AUTOSAR XML (schema 4-2-1)
standard types defined: boolean, float32, float64, sint16, uint16, uint32, uint8, boolean_CompuMethod, boolean_DataConstr, float32_DataConstr, float64_DataConstr, sint16_DataConstr, uint16_DataConstr, uint32_DataConstr, uint8_DataConstr
package /ComponentTypes
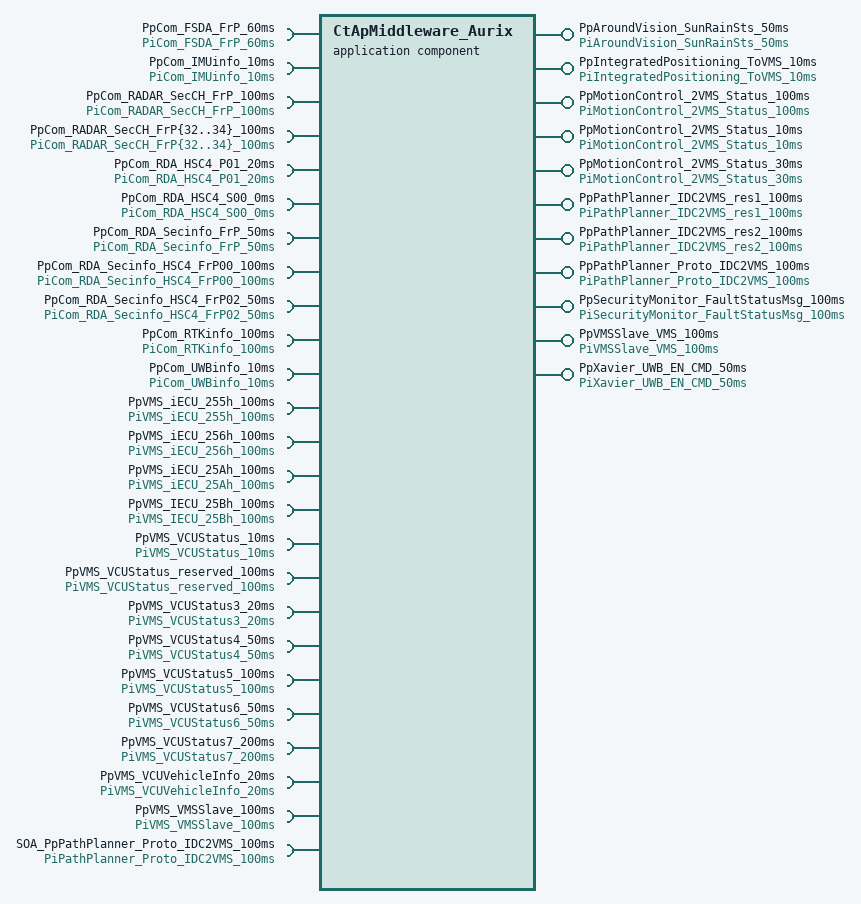
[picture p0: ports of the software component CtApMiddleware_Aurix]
  application sw component type CtApMiddleware_Aurix
    11 x provide port:
      PpAroundVision_SunRainSts_50ms: nonqueued-sender-com-spec{data-element=DeSunRainSts, init-value=constant-reference=C_RECORD_SunRainSts}, provided-interface=PiAroundVision_SunRainSts_50ms
      PpIntegratedPositioning_ToVMS_10ms: nonqueued-sender-com-spec{data-element=DeIntegratedPositioning_ToVMS, init-value=constant-reference=C_RECORD_IntegratedPositioning_ToVMS}, provided-interface=PiIntegratedPositioning_ToVMS_10ms
      PpMotionControl_2VMS_Status_100ms: provided-interface=PiMotionControl_2VMS_Status_100ms
        provided-com-specs:
          data-element=DeCtrl_IDCCAN_IDCStatus{10..19}, init-value=constant-reference=C_RECORD_Ctrl_IDCCAN_IDCStatus{10..19}
          data-element=DeCtrl_IDCCAN_IDCStatus9, init-value=constant-reference=C_RECORD_Ctrl_IDCCAN_IDCStatus9
      PpMotionControl_2VMS_Status_10ms: provided-interface=PiMotionControl_2VMS_Status_10ms
        provided-com-specs:
          data-element=DeCtrl_IDCCAN_IDCStatus{5..7}, init-value=constant-reference=C_RECORD_Ctrl_IDCCAN_IDCStatus{5..7}
      PpMotionControl_2VMS_Status_30ms: provided-interface=PiMotionControl_2VMS_Status_30ms
        provided-com-specs:
          data-element=DeCtrl_IDCCAN_IDCStatus{1..4}, init-value=constant-reference=C_RECORD_Ctrl_IDCCAN_IDCStatus{1..4}
      PpPathPlanner_IDC2VMS_res1_100ms: nonqueued-sender-com-spec{data-element=DeIDC2VMS_res1, init-value=constant-reference=C_RECORD_IDC2VMS_res1}, provided-interface=PiPathPlanner_IDC2VMS_res1_100ms
      PpPathPlanner_IDC2VMS_res2_100ms: nonqueued-sender-com-spec{data-element=DeIDC2VMS_res2, init-value=constant-reference=C_RECORD_IDC2VMS_res2}, provided-interface=PiPathPlanner_IDC2VMS_res2_100ms
      PpPathPlanner_Proto_IDC2VMS_100ms: nonqueued-sender-com-spec{data-element=DeProto_IDC2VMS, init-value=constant-reference=C_RECORD_Proto_IDC2VMS}, provided-interface=PiPathPlanner_Proto_IDC2VMS_100ms
      PpSecurityMonitor_FaultStatusMsg_100ms: nonqueued-sender-com-spec{data-element=DeFaultStatusMsg, init-value=constant-reference=C_RECORD_FaultStatusMsg}, provided-interface=PiSecurityMonitor_FaultStatusMsg_100ms
      PpVMSSlave_VMS_100ms: nonqueued-sender-com-spec{data-element=DeVMSSlave_VMS, init-value=constant-reference=C_RECORD_VMSSlave_VMS_100ms}, provided-interface=PiVMSSlave_VMS_100ms
      PpXavier_UWB_EN_CMD_50ms: nonqueued-sender-com-spec{data-element=DeUWB_EN_CMD, init-value=constant-reference=C_RECORD_UWB_EN_CMD}, provided-interface=PiXavier_UWB_EN_CMD_50ms
    27 x require port:
      PpCom_FSDA_FrP_60ms: nonqueued-receiver-com-spec{data-element=DeFSDA_FrP_f1_s2, filter=data-filter-type=ALWAYS, init-value=constant-reference=C_ARRAY_32_FSDA_FrP}, required-interface=PiCom_FSDA_FrP_60ms
      PpCom_IMUinfo_10ms: nonqueued-receiver-com-spec{data-element=DeIMUinfo, filter=data-filter-type=ALWAYS, init-value=constant-reference=C_RECORD_IMUinfo}, required-interface=PiCom_IMUinfo_10ms
      PpCom_RADAR_SecCH_FrP_100ms: nonqueued-receiver-com-spec{data-element=DeRADAR_SecCH_FrP_f2_s2, filter=data-filter-type=ALWAYS, init-value=constant-reference=C_ARRAY_32_RADAR_SecCH_FrP}, required-interface=PiCom_RADAR_SecCH_FrP_100ms
      PpCom_RADAR_SecCH_FrP{32..34}_100ms: nonqueued-receiver-com-spec{data-element=DeRADAR_SecCH_FrP{32..34}, filter=data-filter-type=ALWAYS, init-value=constant-reference=C_RECORD_RADAR_SecCH_FrP{32..34}}, required-interface=PiCom_RADAR_SecCH_FrP{32..34}_100ms
      PpCom_RDA_HSC4_P01_20ms: nonqueued-receiver-com-spec{data-element=DeRDA_HSC4_P01, filter=data-filter-type=ALWAYS, init-value=constant-reference=C_RECORD_RDA_HSC4_P01}, required-interface=PiCom_RDA_HSC4_P01_20ms
      PpCom_RDA_HSC4_S00_0ms: nonqueued-receiver-com-spec{data-element=DeRDA_HSC4_S00, filter=data-filter-type=ALWAYS, init-value=constant-reference=C_RECORD_RDA_HSC4_S00}, required-interface=PiCom_RDA_HSC4_S00_0ms
      PpCom_RDA_Secinfo_FrP_50ms: nonqueued-receiver-com-spec{data-element=DeRDA_Secinfo_FrP_f2_s9, filter=data-filter-type=ALWAYS, init-value=constant-reference=C_ARRAY_20_RDA_Secinfo_FrP}, required-interface=PiCom_RDA_Secinfo_FrP_50ms
      PpCom_RDA_Secinfo_HSC4_FrP00_100ms: nonqueued-receiver-com-spec{data-element=DeRDA_Secinfo_HSC4_FrP00, filter=data-filter-type=ALWAYS, init-value=constant-reference=C_RECORD_RDA_Secinfo_HSC4_FrP00}, required-interface=PiCom_RDA_Secinfo_HSC4_FrP00_100ms
      PpCom_RDA_Secinfo_HSC4_FrP02_50ms: nonqueued-receiver-com-spec{data-element=DeRDA_Secinfo_HSC4_FrP02, filter=data-filter-type=ALWAYS, init-value=constant-reference=C_RECORD_RDA_Secinfo_HSC4_FrP02}, required-interface=PiCom_RDA_Secinfo_HSC4_FrP02_50ms
      PpCom_RTKinfo_100ms: nonqueued-receiver-com-spec{data-element=DeRTKinfo, filter=data-filter-type=ALWAYS, init-value=constant-reference=C_RECORD_RTKinfo}, required-interface=PiCom_RTKinfo_100ms
      PpCom_UWBinfo_10ms: nonqueued-receiver-com-spec{data-element=DeUWBinfo, filter=data-filter-type=ALWAYS, init-value=constant-reference=C_RECORD_UWBinfo}, required-interface=PiCom_UWBinfo_10ms
      PpVMS_iECU_255h_100ms: nonqueued-receiver-com-spec{data-element=DeiECU_255h, filter=data-filter-type=ALWAYS, init-value=constant-reference=C_RECORD_iECU_255h}, required-interface=PiVMS_iECU_255h_100ms
      PpVMS_iECU_256h_100ms: nonqueued-receiver-com-spec{data-element=DeiECU_256h, filter=data-filter-type=ALWAYS, init-value=constant-reference=C_RECORD_iECU_256h}, required-interface=PiVMS_iECU_256h_100ms
      PpVMS_iECU_25Ah_100ms: nonqueued-receiver-com-spec{data-element=DeiECU_25Ah, filter=data-filter-type=ALWAYS, init-value=constant-reference=C_RECORD_iECU_25Ah}, required-interface=PiVMS_iECU_25Ah_100ms
      PpVMS_IECU_25Bh_100ms: nonqueued-receiver-com-spec{data-element=DeIECU_25Bh, filter=data-filter-type=ALWAYS, init-value=constant-reference=C_RECORD_IECU_25Bh}, required-interface=PiVMS_IECU_25Bh_100ms
      PpVMS_VCUStatus_10ms: nonqueued-receiver-com-spec{data-element=DeVCUStatus, filter=data-filter-type=ALWAYS, init-value=constant-reference=C_RECORD_VCUStatus}, required-interface=PiVMS_VCUStatus_10ms
      PpVMS_VCUStatus_reserved_100ms: nonqueued-receiver-com-spec{data-element=DeVCUStatus_reserved, filter=data-filter-type=ALWAYS, init-value=constant-reference=C_RECORD_VCUStatus_reserved}, required-interface=PiVMS_VCUStatus_reserved_100ms
      PpVMS_VCUStatus3_20ms: nonqueued-receiver-com-spec{data-element=DeVCUStatus3, filter=data-filter-type=ALWAYS, init-value=constant-reference=C_RECORD_VCUStatus3}, required-interface=PiVMS_VCUStatus3_20ms
      PpVMS_VCUStatus4_50ms: nonqueued-receiver-com-spec{data-element=DeVCUStatus4, filter=data-filter-type=ALWAYS, init-value=constant-reference=C_RECORD_VCUStatus4}, required-interface=PiVMS_VCUStatus4_50ms
      PpVMS_VCUStatus5_100ms: nonqueued-receiver-com-spec{data-element=DeVCUStatus5, filter=data-filter-type=ALWAYS, init-value=constant-reference=C_RECORD_VCUStatus5}, required-interface=PiVMS_VCUStatus5_100ms
      PpVMS_VCUStatus6_50ms: nonqueued-receiver-com-spec{data-element=DeVCUStatus6, filter=data-filter-type=ALWAYS, init-value=constant-reference=C_RECORD_VCUStatus6}, required-interface=PiVMS_VCUStatus6_50ms
      PpVMS_VCUStatus7_200ms: nonqueued-receiver-com-spec{data-element=DeVCUStatus7, filter=data-filter-type=ALWAYS, init-value=constant-reference=C_RECORD_VCUStatus7}, required-interface=PiVMS_VCUStatus7_200ms
      PpVMS_VCUVehicleInfo_20ms: nonqueued-receiver-com-spec{data-element=DeVCUVehicleInfo, filter=data-filter-type=ALWAYS, init-value=constant-reference=C_RECORD_VCUVehicleInfo}, required-interface=PiVMS_VCUVehicleInfo_20ms
      PpVMS_VMSSlave_100ms: nonqueued-receiver-com-spec{data-element=DeVMS_VMSSlave, filter=data-filter-type=ALWAYS, init-value=constant-reference=C_RECORD_VMS_VMSSlave}, required-interface=PiVMS_VMSSlave_100ms
      SOA_PpPathPlanner_Proto_IDC2VMS_100ms: nonqueued-receiver-com-spec{data-element=DeProto_IDC2VMS, filter=data-filter-type=ALWAYS, init-value=constant-reference=C_RECORD_Proto_IDC2VMS}, required-interface=PiPathPlanner_Proto_IDC2VMS_100ms
    behavior CtApMiddleware_Aurix_InternalBehavior
  swc implementation CtApMiddleware_Aurix_Implementation: behavior=CtApMiddleware_Aurix_InternalBehavior
    code-descriptors:
      code Default: artifact-descriptors=autosar-engineering-object={short-label=Default, category=SWSRC}
package /Constants
  110 x constant specification:
    C_ARRAY_10_float32: value-spec=10 x 0
    C_ARRAY_20_RDA_Secinfo_FrP: value-spec=20 x C_RECORD_RDA_Secinfo_FrP
    C_ARRAY_32_FSDA_FrP: value-spec=32 x C_RECORD_FSDA_FrP
    C_ARRAY_32_RADAR_SecCH_FrP: value-spec=32 x C_RECORD_RADAR_SecCH_FrP
    C_RECORD_AccBias_Lcc: value-spec=fields=[AxBiassecinfo:0, AyBiassecinfo:0, AzBiassecinfo:0, Lccsecinfo:0]
    C_RECORD_Acce_AngularVel_X: value-spec=fields=[AccelerationXsecinfo:0, AngularRateXsecinfo:0]
    C_RECORD_Acce_AngularVel_Y: value-spec=fields=[AccelerationYsecinfo:0, AngularRateYsecinfo:0]
    C_RECORD_Acce_AngularVel_Z: value-spec=fields=[AccelerationZsecinfo:0, AngularRateZsecinfo:0]
    C_RECORD_AtterrStatus2: value-spec=fields=[PitchStdsecinfo:0, RollStdsecinfo:0, VelDStdsecinfo:0, VelEStdsecinfo:0, VelNStdsecinfo:0, YawStdsecinfo:0]
    C_RECORD_BaseInfoRTK: value-spec=fields=[EastDistancRTK:0, NorthDistancRTK:0]
    C_RECORD_Ctrl_IDCCAN_IDCStatus1: value-spec=fields=[{short-label=stHeader, constant=C_RECORD_HEADER}, fStrgWhlAngReq_degHSC4:0, bEngToqReqVHSC4:0, bStrgWhlAngGrdReqV_degpsHSC4:0, bStrgWhlAngReqV_degHSC4:0, bStrgWhlToqReqV_NmHSC4:0, fEngToqReqHSC4:0, fStrgWhlAngGrdReq_degpsHSC4:0, fStrgWhlToqReq_NmHSC4:0, PaddingGap16_1:0, PaddingGap16_2:0]
    C_RECORD_Ctrl_IDCCAN_IDCStatus10: value-spec=fields=[{short-label=stHeader, constant=C_RECORD_HEADER}, nRCar2AurixReserve100ms_5:0, nRCar2AurixReserve100ms_6:0, nRCar2AurixReserve100ms_7:0, nRCar2AurixReserve100ms_8:0]
    C_RECORD_Ctrl_IDCCAN_IDCStatus11: value-spec=fields=[{short-label=stHeader, constant=C_RECORD_HEADER}, nRCar2AurixReserve100ms_9:0, nRCar2AurixReserve100ms_10:0, nRCar2AurixReserve100ms_11:0, nRCar2AurixReserve100ms_12:0]
    C_RECORD_Ctrl_IDCCAN_IDCStatus12: value-spec=fields=[{short-label=stHeader, constant=C_RECORD_HEADER}, fRCar2AurixReserve100ms_1:0, fRCar2AurixReserve100ms_2:0, fRCar2AurixReserve100ms_3:0, fRCar2AurixReserve100ms_4:0]
    C_RECORD_Ctrl_IDCCAN_IDCStatus13: value-spec=fields=[{short-label=stHeader, constant=C_RECORD_HEADER}, fRCar2AurixReserve100ms_5:0, fRCar2AurixReserve100ms_6:0, fRCar2AurixReserve100ms_7:0, fRCar2AurixReserve100ms_8:0]
    C_RECORD_Ctrl_IDCCAN_IDCStatus14: value-spec=fields=[{short-label=stHeader, constant=C_RECORD_HEADER}, fRCar2AurixReserve100ms_9:0, fRCar2AurixReserve100ms_10:0, fRCar2AurixReserve100ms_11:0, fRCar2AurixReserve100ms_12:0]
    C_RECORD_Ctrl_IDCCAN_IDCStatus15: value-spec=fields=[{short-label=stHeader, constant=C_RECORD_HEADER}, fRCar2AurixReserve100ms_13:0, fRCar2AurixReserve100ms_14:0, fRCar2AurixReserve100ms_15:0, fRCar2AurixReserve100ms_16:0]
    C_RECORD_Ctrl_IDCCAN_IDCStatus16: value-spec=fields=[{short-label=stHeader, constant=C_RECORD_HEADER}, fRCar2AurixReserve100ms_17:0, fRCar2AurixReserve100ms_18:0, fRCar2AurixReserve100ms_19:0, fRCar2AurixReserve100ms_20:0]
    C_RECORD_Ctrl_IDCCAN_IDCStatus17: value-spec=fields=[{short-label=stHeader, constant=C_RECORD_HEADER}, fRCar2AurixReserve100ms_21:0, fRCar2AurixReserve100ms_22:0, fRCar2AurixReserve100ms_23:0, fRCar2AurixReserve100ms_24:0]
    C_RECORD_Ctrl_IDCCAN_IDCStatus18: value-spec=fields=[{short-label=stHeader, constant=C_RECORD_HEADER}, fRCar2AurixReserve100ms_25:0, fRCar2AurixReserve100ms_26:0, fRCar2AurixReserve100ms_27:0, fRCar2AurixReserve100ms_28:0]
    C_RECORD_Ctrl_IDCCAN_IDCStatus19: value-spec=fields=[{short-label=stHeader, constant=C_RECORD_HEADER}, fRCar2AurixReserve100ms_29:0, fRCar2AurixReserve100ms_30:0, fRCar2AurixReserve100ms_31:0, fRCar2AurixReserve100ms_32:0]
    C_RECORD_Ctrl_IDCCAN_IDCStatus2: value-spec=fields=[{short-label=stHeader, constant=C_RECORD_HEADER}, bDecAccReqV_mpssHSC4:0, bDecPressureReqV_barHSC4:0, bShifterPosReqVHSC4:0, PaddingGap8_1:0, fDecAccReq_mpssHSC4:0, fDecPressureReq_barHSC4:0, nEPBReqHSC4:0, nRCarAlv10msRCHSC4:0, nSCSDriverOffReqHSC4:0, nSCSStandStillReqHSC4:0, nShifterPosReqHSC4:0, PaddingGap8_2:0, PaddingGap16_3:0, PaddingGap16_4:0, PaddingGap16_5:0]
    C_RECORD_Ctrl_IDCCAN_IDCStatus3: value-spec=fields=[{short-label=stHeader, constant=C_RECORD_HEADER}, fRCar2AurixReserve30ms_1:0, fRCar2AurixReserve30ms_2:0, fRCar2AurixReserve30ms_3:0, fRCar2AurixReserve30ms_4:0]
    C_RECORD_Ctrl_IDCCAN_IDCStatus4: value-spec=fields=[{short-label=stHeader, constant=C_RECORD_HEADER}, nRCar2AurixReserve30ms_1:0, nRCar2AurixReserve30ms_2:0, nRCar2AurixReserve30ms_3:0, nRCar2AurixReserve30ms_4:0]
    C_RECORD_Ctrl_IDCCAN_IDCStatus5: value-spec=fields=[{short-label=stHeader, constant=C_RECORD_HEADER}, fRCar2AurixReserve10ms_1:0, fRCar2AurixReserve10ms_2:0, fRCar2AurixReserve10ms_3:0, fRCar2AurixReserve10ms_4:0]
    C_RECORD_Ctrl_IDCCAN_IDCStatus6: value-spec=fields=[{short-label=stHeader, constant=C_RECORD_HEADER}, fRCar2AurixReserve10ms_5:0, fRCar2AurixReserve10ms_6:0, fRCar2AurixReserve10ms_7:0, fRCar2AurixReserve10ms_8:0]
    C_RECORD_Ctrl_IDCCAN_IDCStatus7: value-spec=fields=[{short-label=stHeader, constant=C_RECORD_HEADER}, nRCar2AurixReserve10ms_1:0, nRCar2AurixReserve10ms_2:0, nRCar2AurixReserve10ms_3:0, nRCar2AurixReserve10ms_4:0]
    C_RECORD_Ctrl_IDCCAN_IDCStatus9: value-spec=fields=[{short-label=stHeader, constant=C_RECORD_HEADER}, nRCar2AurixReserve100ms_1:0, nRCar2AurixReserve100ms_2:0, nRCar2AurixReserve100ms_3:0, nRCar2AurixReserve100ms_4:0]
    C_RECORD_Diagnosticmessage: value-spec=fields=[Rightsidequalityofantennasignal:0, Leftsidequalityofantennasignal:0, CANprotocolinternalversion:0, GNSSReceiverstartupstatus:0, AGNSSephemerisreceivedstatus:0, CANdatasendstatus:0, Mobilenetwork:0, RightsideGNSSAntennastatus:0, LeftsideGNSSAntennastatus:0, PaddingGap8_1:0, PaddingGap16_2:0]
    C_RECORD_Diagnosticmessage_IMU: value-spec=fields=[DiffDataLinkBrokensecinfo:0, GNSSAntenasBrokensecinfo:0, GPSMsgErrInIMUsecinfo:0, IECUMsgErrInIMUsecinfo:0]
    C_RECORD_ETC1: value-spec=fields=[TransDrivelineEngaged:0, TransTorqueConverterLockupEngag:0, TransShiftlnProcess:0, PaddingGap8_1:0, TransOutputShaftSpeed:0, PercentClutchSlip:0, EngineMomentaryOverspeedEnable:0, ProgressiveShiftDisable:0, PaddingGap16_2:0, TransInputShaftSpeed:0, SrcAddressCtrlDeviceForTransCtrl:0, PaddingGap8_3:0, PaddingGap16_4:0]
    C_RECORD_FaultStatusMsg: value-spec=fields=[{short-label=stHeader, constant=C_RECORD_HEADER}, FailureBitChassis:0, FailureBitEyeQ4:0, FailureBitIECU:0, FailureBitLidar:0, FailureBitAV:0, FailureBitSV:0, FailureBitCAN:0, FailureBitLoc:0, FailureBitIBOX:0, FailureBitReserved_1:0, {short-label=FailureBitReserved, constant=C_ARRAY_10_float32}, Action:0, FailureBitReserved_2:0, Level:0, PaddingGap16_1:0, PaddingGap16_2:0]
    C_RECORD_FSDA_FrP: value-spec=fields=[FSDA_FrP_yspeed:0, FSDA_FrP_ypoint:0, FSDA_FrP_xspeed:0, FSDA_FrP_xpoint:0, FSDA_FrP_V:0, FSDA_FrP_rollingcn:0, FSDA_FrP_id:0, PaddingGap8_1:0]
    C_RECORD_GPS_ECUStatus: value-spec=fields=[ECUWarningsecinfo:0, GPSHeadingStatussecinfo:0, GPSPosStatussecinfo:0, PaddingGap8_1:0, GPSStatussecinfo:0, GPSVelStatussecinfo:0, GPSWarningsecinfo:0, RTKDelaysecinfo:0, VehiclesStatussecinfo:0, PaddingGap16_2:0]
    C_RECORD_GPSPos_HeadingPrecison: value-spec=fields=[AltSigmaGPSsecinfo:0, HeadingSigmaGPSsecinfo:0, LatSigmaGPSsecinfo:0, LonSigmaGPSsecinfo:0]
    C_RECORD_GPSVel_PitchPrecison: value-spec=fields=[PitchSigmaGPSsecinfo:0, VeldownsigmaGPSsecinfo:0, VeleastsigmaGPSsecinfo:0, VelnorthsigmaGPSsecinfo:0]
    C_RECORD_GyroBias_Kws: value-spec=fields=[GxBiassecinfo:0, GyBiassecinfo:0, GzBiassecinfo:0, Kwssecinfo:0]
    C_RECORD_HEADER: value-spec=fields=[TimeStamp:0, FrameID:0, status:0, Counter:0, PaddingGap16_1:0, PaddingGap16_2:0]
    C_RECORD_HeadingPitchInfoRTK: value-spec=fields=[PitchSigma:0, HeadingSigma:0, PitchRTK:0, HeadingRTK:0]
    C_RECORD_IDC2VMS_res1: value-spec=fields=[{short-label=stHeader, fields=[TimeStamp:0, FrameID:0, PaddingGap8_1:0, Counter:0, PaddingGap16_1:0, PaddingGap16_2:0]}, reseverd_float64:100 x 0]
    C_RECORD_IDC2VMS_res2: value-spec=fields=[{short-label=stHeader, fields=[TimeStamp:0, FrameID:0, PaddingGap8_1:0, Counter:0, PaddingGap16_1:0, PaddingGap16_2:0]}, reserved_float64:100 x 0]
    C_RECORD_iECU_250h: value-spec=fields=SA_AngleValue:0
    C_RECORD_iECU_255h: value-spec=fields=[iECU_PEGSUS_pilotWarning:0, iECU_PEGSUS_pilotStatus:0, PaddingGap16_1:0, iECU_pilotDisableInfo:0, iECU_pilot_OverrideIndicator:0, PaddingGap8_2:0, PaddingGap16_3:0]
    C_RECORD_iECU_256h: value-spec=fields=[iECU_pilot_Steer_Override:0, PaddingGap8_1:0, PaddingGap16_2:0]
    C_RECORD_iECU_25Ah: value-spec=fields=[iECU_PEGSUS_AEBState:0, PaddingGap8_1:0, PaddingGap16_2:0]
    C_RECORD_IECU_25Bh: value-spec=fields=[LockandTwistSwitch:0, PaddingGap8_1:0, PaddingGap16_2:0]
    C_RECORD_IECU_FMS1: value-spec=fields=[HighResolutionTripDistance_FMS:0, HghRsolTotalVehDistance_FMS:0]
    C_RECORD_IECU_FMS2: value-spec=fields=[Byte7:0, ResidualLiquidLevel_FMS:0, PaddingGap16_1:0]
    C_RECORD_IECU1toPegasus: value-spec=fields=[FailureBitODFSIECU1:0, FailureBitActor01:0]
    C_RECORD_IECUInternal: value-spec=fields=[Byte3:0, FailureBitIECU1Internal:0]
    C_RECORD_IMUinfo: value-spec=fields=[{short-label=Acce_AngularVel_X, constant=C_RECORD_Acce_AngularVel_X}, {short-label=Acce_AngularVel_Y, constant=C_RECORD_Acce_AngularVel_Y}, {short-label=Acce_AngularVel_Z, constant=C_RECORD_Acce_AngularVel_Z}, {short-label=AtterrStatus2, constant=C_RECORD_AtterrStatus2}, {short-label=INSAltitude_VelDown, constant=C_RECORD_INSAltitude_VelDown}, {short-label=INSLatitudeInfo, constant=C_RECORD_INSLatitudeInfo}, {short-label=INSLongitudeInfo, constant=C_RECORD_INSLongitudeInfo}, {short-label=NavStatus_Heading, constant=C_RECORD_NavStatus_Heading}, {short-label=Pitch_Roll, constant=C_RECORD_Pitch_Roll}, {short-label=PoserrStatus1, constant=C_RECORD_PoserrStatus1}, {short-label=StatusInfo, constant=C_RECORD_StatusInfo}, {short-label=VelNorthEast, constant=C_RECORD_VelNorthEast}, {short-label=AccBias_Lcc, constant=C_RECORD_AccBias_Lcc}, {short-label=GPS_ECUStatus, constant=C_RECORD_GPS_ECUStatus}, {short-label=GPSPos_HeadingPrecison, constant=C_RECORD_GPSPos_HeadingPrecison}, {short-label=GPSVel_PitchPrecison, constant=C_RECORD_GPSVel_PitchPrecison}, {short-label=GyroBias_Kws, constant=C_RECORD_GyroBias_Kws}, {short-label=INSATB, constant=C_RECORD_INSATB}, {short-label=INSATG, constant=C_RECORD_INSATG}, {short-label=INSLTC_LTG, constant=C_RECORD_INSLTC_LTG}, {short-label=VersionNumber, constant=C_RECORD_VersionNumber}, {short-label=Diagnosticmessage_IMU, constant=C_RECORD_Diagnosticmessage_IMU}, {short-label=INSTIme, constant=C_RECORD_INSTIme}, {short-label=ReservedMsg, constant=C_RECORD_ReservedMsg}]
    C_RECORD_INSAltitude_VelDown: value-spec=fields=[AltitudeINSsecinfo:0, DownVelocitysecinfo:0]
    C_RECORD_INSATB: value-spec=fields=[ATB_pitchsecinfo:0, ATB_rollsecinfo:0, ATB_yawsecinfo:0]
    C_RECORD_INSATG: value-spec=fields=[ATG_pitchsecinfo:0, ATG_rollsecinfo:0, ATG_yawsecinfo:0]
    C_RECORD_INSLatitudeInfo: value-spec=fields=LatitudeINSsecinfo:0
    C_RECORD_INSLongitudeInfo: value-spec=fields=LongitudeINSsecinfo:0
    C_RECORD_INSLTC_LTG: value-spec=fields=[LTC_xsecinfo:0, LTC_ysecinfo:0, LTC_zsecinfo:0, LTG_xsecinfo:0, LTG_ysecinfo:0, LTG_zsecinfo:0]
    C_RECORD_INSTIme: value-spec=fields=[UTCTime_YDM:0, UTCTime_HMSssss_IMU:0]
    C_RECORD_IntegratedPositioning_ToVMS: value-spec=fields=[{short-label=stHeader, fields=[TimeStamp:0, FrameID:0, PaddingGap8_1:0, Counter:0, PaddingGap16_1:0, PaddingGap16_2:0]}, time_sec:0, data_name:0, valid:0, PaddingGap16_1:0, weight:0, {short-label=pos_real, fields=[longitude:0, latitude:0, height:0]}, {short-label=pos_utm_real, fields=[X:0, Y:0, Z:0]}, {short-label=pos_Encryption, fields=[longitude:0, latitude:0, height:0]}, {short-label=pos_utm_Encryption, fields=[X:0, Y:0, Z:0]}, {short-label=vel, fields=[north:0, east:0, down:0]}, {short-label=att, fields=[roll:0, pitch:0, heading:0]}, heading_reverse:0, heading_reverse_flag:0, PaddingGap8_2:0, PaddingGap16_3:0, {short-label=cal_line_acc, fields=[X:0, Y:0, Z:0]}, {short-label=cal_line_anglerate, fields=[X:0, Y:0, Z:0]}, PaddingGap16_4:0, PaddingGap16_5:0, lasttime_sec:0, deltaime:0, PaddingGap16_6:0, PaddingGap16_7:0, {short-label=delta_pos_deg, fields=[longitude:0, latitude:0, height:0]}, {short-label=delta_pos_XYZ, fields=[X:0, Y:0, Z:0]}, {short-label=delta_vel_m_s, fields=[north:0, east:0, down:0]}, {short-label=delta_att_rad, fields=[roll:0, pitch:0, heading:0]}, PaddingGap16_8:0, PaddingGap16_9:0, tag_reserve_double:9 x 9 x 0, tag_reserve_int:9 x 9 x 0, sensor_qosstate:0, couple_flag:0, reset_flag:0, sensor_originaldata_qosstate:0, sensor_dataflowstate:0, crd_def:0, hasbeenusedinkf_flag:0, iIntegratedPositionMode:0, iIntegratedVelMode:0, iIntegratedOrientationMode:0, 0, 0, 0, 0, pos_valid:0, vel_valid:0, att_valid:0, PaddingGap16_10:0, PaddingGap16_11:0, PaddingGap16_12:0, gpstime_sec:0]
    C_RECORD_LatitudeInfoRTK: value-spec=fields=[UTCTime_YMD:0, PaddingGap16_1:0, PaddingGap16_2:0, LatitudeRTK:0]
    C_RECORD_LongitudeInfoRTK: value-spec=fields=[AltitudeRTK:0, PaddingGap16_1:0, PaddingGap16_2:0, LongitudeRTK:0]
    C_RECORD_MasterSlaveRTK: value-spec=fields=[PositionAttitudeStatus:0, DiffAgeInfo:0, DiffBaseIDInfo:0, Baselinelength:0, SatNoInAttitudeRTK:0, SatNoInPositionRTK:0, PaddingGap16_1:0]
    C_RECORD_NavStatus_Heading: value-spec=fields=[ChannelInfosecinfo:0, PaddingGap8_1:0, CurrentGPSTimesecinfo:0, Headingsecinfo:0, NavStatussecinfo:0, PaddingGap8_2:0, PaddingGap16_3:0]
    C_RECORD_Pitch_Roll: value-spec=fields=[Pitchsecinfo:0, Rollsecinfo:0]
    C_RECORD_PoserrStatus1: value-spec=fields=[AltStdsecinfo:0, LatStdsecinfo:0, LonStdsecinfo:0]
    C_RECORD_PositionInfoRTK: value-spec=fields=[UTCTime_HMSssss_RTK:0, SerialNumberRTK:0]
    C_RECORD_PositionSigma: value-spec=fields=[AltSigma:0, LonSigma:0, LatSigma:0]
    C_RECORD_Proto_IDC2VMS: value-spec=fields=[TimeStamp:0, Counter:0, IDCReady:0, PaddingGap8_1:0, IDCDTC:0, IDC2VMSPV:0, NoTechniqueTakeOverValid:0, TaskStage:0, PaddingGap16_2:0, PaddingGap16_3:0, PaddingGap16_4:0, IDCBehavior:0, AdpStatus:0, PaddingGap8_5:0, PaddingGap16_6:0, TrackCoefficiantX1:0, TrackCoefficiantX1V:0, PaddingGap8_7:0, PaddingGap16_8:0, TrackCoefficiantX2:0, TrackCoefficiantX2V:0, PaddingGap8_9:0, PaddingGap16_10:0, TrackCoefficiantX3:0, TrackCoefficiantX3V:0, PaddingGap8_11:0, PaddingGap16_12:0, TrackCoefficiantX4:0, TrackCoefficiantX4V:0, PaddingGap8_13:0, PaddingGap16_14:0, TrackCoefficiantX5:0, TrackCoefficiantX5V:0, PaddingGap8_15:0, PaddingGap16_16:0, TrackCoefficiantY1:0, TrackCoefficiantY1V:0, PaddingGap8_17:0, PaddingGap16_18:0, TrackCoefficiantY2:0, TrackCoefficiantY2V:0, PaddingGap8_19:0, PaddingGap16_20:0, TrackCoefficiantY3:0, TrackCoefficiantY3V:0, PaddingGap8_21:0, PaddingGap16_22:0, TrackCoefficiantY4:0, TrackCoefficiantY4V:0, PaddingGap8_23:0, PaddingGap16_24:0, TrackCoefficiantY5:0, TrackCoefficiantY5V:0, PaddingGap8_25:0, PaddingGap16_26:0, PathLength:0, TrackCoefficiantX1_Global:0, TrackCoefficiantX1V_Global:0, PaddingGap8_27:0, PaddingGap16_28:0, TrackCoefficiantX2_Global:0, TrackCoefficiantX2V_Global:0, PaddingGap8_29:0, PaddingGap16_30:0, TrackCoefficiantX3_Global:0, TrackCoefficiantX3V_Global:0, PaddingGap8_31:0, PaddingGap16_32:0, TrackCoefficiantX4_Global:0, TrackCoefficiantX4V_Global:0, PaddingGap8_33:0, PaddingGap16_34:0, TrackCoefficiantX5_Global:0, TrackCoefficiantX5V_Global:0, PaddingGap8_35:0, PaddingGap16_36:0, TrackCoefficiantY1_Global:0, TrackCoefficiantY1V_Global:0, PaddingGap8_37:0, PaddingGap16_38:0, TrackCoefficiantY2_Global:0, TrackCoefficiantY2V_Global:0, PaddingGap8_39:0, PaddingGap16_40:0, TrackCoefficiantY3_Global:0, TrackCoefficiantY3V_Global:0, PaddingGap8_41:0, PaddingGap16_42:0, TrackCoefficiantY4_Global:0, TrackCoefficiantY4V_Global:0, PaddingGap8_43:0, PaddingGap16_44:0, TrackCoefficiantY5_Global:0, TrackCoefficiantY5V_Global:0, PaddingGap8_45:0, PaddingGap16_46:0, PathLength_Global:0, RoadFollowError:0, FrontRoadFollowError:0, HeadingFollowError:0, PathRadiumMin:0, PathRadiumAvg:0, RounterChange:0, SteeringWheelAngleCmdValid:0, PaddingGap16_47:0, SteeringWheelAngleCmd:0, SteeringWheelAngleGrdCmd:0, IsParkInTaskStage:0, PaddingGap8_48:0, PaddingGap16_49:0, ParkLotTopPointY:0, ParkLotTopPointX:0, ParkLotAngleError:0, TrailerAngle:0, TrailerRoadFollowError:0, IsStraightLineControlMode:0, ChangeLaneMode:0, ReverseMode:0, PaddingGap8_50:0, LaneWidth:0, VehicleSpeedMaxLimit:0, LongitudinalAccRequest:0, VehicleSpeedRequest:0, ShiferPoseRequest:0, PaddingGap8_51:0, PaddingGap16_52:0, DistanceToStop:0, IDCDriveEnvironment:0, BrakeMode:0, DippedBeamLampCmd:0, MainBeamLampCmd:0, LeftDirectionLampCmd:0, RightDirectionLampCmd:0, HornCmd:0, WiperCmd:0, PaddingGap16_53:0, PaddingGap16_54:0, Longitude:0, Latitude:0, Altitude:0, Heading:0, Pitch:0, Roll:0, LongitudinalAcc:0, LateralAcc:0, YawRate:0, Reserved_uint8:10 x 0, Reserved_sint16:10 x 0, PaddingGap16_55:0, Reserved_float32:200 x 0, PaddingGap16_56:0, PaddingGap16_57:0]
    C_RECORD_RADAR_SecCH_FrP: value-spec=fields=[RADAR_SecCH_FrP_ID:0, PaddingGap8_1:0, PaddingGap16_2:0, RADAR_SecCH_FrP_dy:0, RADAR_SecCH_FrP_Vy:0, RADAR_SecCH_FrP_dx:0, RADAR_SecCH_FrP_Vx:0, RADAR_SecCH_FrP_SyncCtr:0, PaddingGap8_3:0, PaddingGap16_4:0, RADAR_SecCH_FrP_wExist:0, RADAR_SecCH_FrP_wObstacle:0]
    C_RECORD_RADAR_SecCH_FrP32: value-spec=fields=[AlignmentFail_SGUSecHS2:0, HWFail_SGUSecHS2:0, OtherFail_SGUSecHS2:0, Sensor_Dirty_SGUSecHS2:0, SGUFailSecHS2:0, SGUObsDataSyncCtrSecHS2:0, PaddingGap16_1:0, SGUObsDataTmspSecHS2:0]
    C_RECORD_RADAR_SecCH_FrP33: value-spec=fields=[AlignmentFail_TGUSecHS2:0, FCWASecHS2:0, PaddingGap16_1:0, FCWTimeToColSecHS2:0, HWFail_TGUSecHS2:0, ObsDataSyncCtrSecHS2:0, PaddingGap16_2:0, ObsDataTmspSecHS2:0, OtherFail_TGUSecHS2:0, PedtrnColWrnngASecHS2:0, Sensor_Dirty_TGUSecHS2:0, TGUFailSecHS2:0]
    C_RECORD_RADAR_SecCH_FrP34: value-spec=fields=[DngrsObjExistSecHS2:0, DngrsObjId_PSecHS2:0, PaddingGap8_1:0, PaddingGap16_2:0, DngrsObjObstacleSecHS2:0, DngrsObjSyncCtr_PSecHS2:0, PaddingGap8_3:0, PaddingGap16_4:0, DngrsPedExistSecHS2:0, DngrsPedObstacleSecHS2:0, DngrsPedtrnId_PSecHS2:0, DngrsPedtrnSyncCtr_PSecHS2:0, PaddingGap16_5:0]
    C_RECORD_RDA_HSC4_P01: value-spec=fields=[BSDSelStssecinfo:0, LCASelStssecinfo:0, RDASwStssecinfo:0, PaddingGap8_1:0]
    C_RECORD_RDA_HSC4_S00: value-spec=fields=[wake_network_RDAsecinfo:0, PaddingGap8_1:0, PaddingGap16_2:0]
    C_RECORD_RDA_Secinfo_FrP: value-spec=fields=[RDA_ttgt1V_secinfo:0, RDA_ttgt1_id_secinfo:0, PaddingGap16_1:0, RDA_ttgt1_xpoint_secinfo:0, RDA_ttgt1_xspeed_secinfo:0, RDA_ttgt1_ypoint_secinfo:0, RDA_ttgt1_yspeed_secinfo:0]
    C_RECORD_RDA_Secinfo_HSC4_FrP00: value-spec=fields=[keep_network_RDAsecinfo:0, PaddingGap8_1:0, PaddingGap16_2:0]
    C_RECORD_RDA_Secinfo_HSC4_FrP02: value-spec=fields=[DOWSelStssecinfo:0, LBSDAndLCAWrnngsecinfo:0, LDOWWrnngsecinfo:0, LRCTAWrnngsecinfo:0, RBSDAndLCAWrnngsecinfo:0, RCTASelStssecinfo:0, RDASysStasecinfo:0, RDOWWrnngsecinfo:0, RRCTAWrnngsecinfo:0, PaddingGap8_1:0, PaddingGap16_2:0]
    C_RECORD_ReservedMsg: value-spec=fields=[arrayuint32:[0, 0, 0, 0], arrayfloat64:[0, 0, 0, 0]]
    C_RECORD_RTKinfo: value-spec=fields=[{short-label=BaseInfoRTK, constant=C_RECORD_BaseInfoRTK}, {short-label=Diagnosticmessage, constant=C_RECORD_Diagnosticmessage}, {short-label=HeadingPitchInfoRTK, constant=C_RECORD_HeadingPitchInfoRTK}, PaddingGap16_1:0, PaddingGap16_2:0, {short-label=LatitudeInfoRTK, constant=C_RECORD_LatitudeInfoRTK}, {short-label=LongitudeInfoRTK, constant=C_RECORD_LongitudeInfoRTK}, {short-label=MasterSlaveRTK, constant=C_RECORD_MasterSlaveRTK}, {short-label=PositionInfoRTK, constant=C_RECORD_PositionInfoRTK}, {short-label=PositionSigma, constant=C_RECORD_PositionSigma}, {short-label=VelocityInfoRTK, constant=C_RECORD_VelocityInfoRTK}, {short-label=VelocitySigma, constant=C_RECORD_VelocitySigma}, {short-label=ReservedMsg, constant=C_RECORD_ReservedMsg}]
    C_RECORD_StatusInfo: value-spec=fields=[ECUDelaysecinfo:0, ECUFreqsecinfo:0, GPSDelaysecinfo:0, GPSFreqsecinfo:0, INSDelaysecinfo:0, INSStatussecinfo:0, INSWarningsecinfo:0]
    C_RECORD_SunRainSts: value-spec=fields=[SunSts:0, RainSts:0, res_uint16:0, res_uint32:0]
    C_RECORD_UWB_EN_CMD: value-spec=fields=[UWBLocEnCmdFlag:0, PaddingGap8_1:0, UWBLocEnAreaNo:0, UWBLocEnAreaAttr:0, UWBLocEn:0, PaddingGap16_2:0]
    C_RECORD_UWB_LOC: value-spec=fields=[UWBLocAreaNo:0, UWBLocAreaAttr:0, PaddingGap8_1:0, UWBLocY:0, UWBLocX:0, UWBLocCredit:0, UWBLocXUnit:0, UWBLocYUnit:0, UWBLocType:0, UWBLocRollingCounter:0, PaddingGap8_2:0, PaddingGap16_3:0]
    C_RECORD_UWB_STATUS: value-spec=fields=[UWBLocExptTimes:0, UWBLocFailTimes:0, UWBAchRxTimes:0, UWBAchTxTimes:0, UWBUwbRxTimes:0, UWBUwbTxTimes:0, UWBHwStatas6vTemp:0, UWBHwStatas5v2v5:0, UWBHwStatas3v3:0, UWBHwStatas1v2:0, UWBRfStatus:0, UWBDsaStatus:0, UWBLogicStatus:0, UWBAchStatus:0, UWBHwStatusType:0, UWBLocEnErrFlg:0, UWBLocEnStep:0, UWBLocEnStatus:0, UWBStatusHeader:0, UWBTagType:0]
    C_RECORD_UWBinfo: value-spec=fields=[{short-label=UWB_LOC, constant=C_RECORD_UWB_LOC}, {short-label=UWB_STATUS, constant=C_RECORD_UWB_STATUS}]
    C_RECORD_VCUStatus: value-spec=fields=[{short-label=stHeader, constant=C_RECORD_HEADER}, {short-label=ETC1, constant=C_RECORD_ETC1}, {short-label=VCUStatus1, constant=C_RECORD_VCUStatus1}, {short-label=VCUStatus2, constant=C_RECORD_VCUStatus2}, {short-label=VCUStatus8, constant=C_RECORD_VCUStatus8}, {short-label=VCUStatus10, constant=C_RECORD_VCUStatus10}, {short-label=VCUStatusTest1, constant=C_RECORD_VCUStatusTest1}, {short-label=VCUStatusTest2, constant=C_RECORD_VCUStatusTest2}, {short-label=VCUStatusTest3, constant=C_RECORD_VCUStatusTest3}, {short-label=VCUStatusTest4, constant=C_RECORD_VCUStatusTest4}, {short-label=iECU_250h, constant=C_RECORD_iECU_250h}, {short-label=VCUStatus9, constant=C_RECORD_VCUStatus9}, PaddingGap16_1:0, PaddingGap16_2:0]
    C_RECORD_VCUStatus_reserved: value-spec=fields=[{short-label=IECU_FMS1, constant=C_RECORD_IECU_FMS1}, {short-label=IECU_FMS2, constant=C_RECORD_IECU_FMS2}, {short-label=IECU1toPegasus, constant=C_RECORD_IECU1toPegasus}, {short-label=IECUInternal, constant=C_RECORD_IECUInternal}, {short-label=VCUStatus_reserved5, constant=C_RECORD_VCUStatus_reserved5}, {short-label=VCUStatus_reserved6, constant=C_RECORD_VCUStatus_reserved6}, {short-label=ReservedMsg, constant=C_RECORD_ReservedMsg}]
    C_RECORD_VCUStatus_reserved5: value-spec=fields=[Byte9:0, Byte8:0]
    C_RECORD_VCUStatus_reserved6: value-spec=fields=[Byte11:0, Byte10:0]
    C_RECORD_VCUStatus1: value-spec=fields=[RouteComplete:0, SCUShifterLvrPosHSC4:0, PaddingGap16_1:0, EPSMotOtptToqHSC4:0, PtBrkPdlDscrtInptStsVHSC4:0, PtBrkPdlDscrtInptStsHSC4:0, PaddingGap16_2:0, EnSpdHSC4:0, DrivemModeStsHSC4:0, DriveModeReqHSC4:0, PaddingGap16_3:0]
    C_RECORD_VCUStatus10: value-spec=fields=[RNonDrvnWhlRotlDistVHSC2:0, PaddingGap8_1:0, RNonDrvnWhlRotlDistPCHSC2:0, RDrvnWhlRotlDistVHSC2:0, PaddingGap8_2:0, RDrvnWhlRotlDistPlsCtrHSC2:0, LDrvnWhlRotlDistVHSC2:0, PaddingGap8_3:0, LNonDrvnWhlRotlDistPCHSC2:0, LNonDrvnWhlRotlDistVHSC2:0, PaddingGap8_4:0, LDrvnWhlRotlDistPlsCtrHSC2:0]
    C_RECORD_VCUStatus2: value-spec=fields=[StrgWhlAngHSC4:0, StrgWhlAngAlvRCHSC4:0, PaddingGap8_1:0, StrgWhlAngExtdPVHSC4:0, StrgWhlAngGrdHSC4:0, StrgWhlAngSnsrCalStsHSC4:0, StrgWhlAngSnsrChksmHSC4:0, StrgWhlAngSnsrFltHSC4:0, StrgWhlAngSnsrInidHSC4:0, StrgWhlAngSnsrMultCapbHSC4:0, StrgWhlAngVHSC4:0]
    C_RECORD_VCUStatus3: value-spec=fields=[SysVol_HSC4:0, EPBAppcnStsHSC4:0, VehSpdAvgVHSC4:0, PaddingGap16_1:0, VehSpdAvgHSC4:0, VSELongtAccVHSC4:0, PaddingGap8_2:0, PaddingGap16_3:0, VSELongtAccHSC4:0, VehDynYawRateVHSC4:0, PaddingGap8_4:0, PaddingGap16_5:0, VehDynYawRateHSC4:0, AirbagDplHSC4:0, PaddingGap8_6:0, PaddingGap16_7:0]
    C_RECORD_VCUStatus4: value-spec=fields=[VehLckngStaHSC4:0, FrtPsngDoorOpenStsHSC4:0, DrvrDoorOpenStsHSC4:0, VehInertiaSwTrigdHSC4:0, BrkPdlDrvrAppdPrsV_HSC4:0, BrkPdlDrvrAppdPrsAlvRC_HSC4:0, BrkPdlDrvrAppdPrs_HSC4:0, PaddingGap8_1:0]
    C_RECORD_VCUStatus5: value-spec=fields=[VehDeceLmtHSC4:0, VehAcceLmtHSC4:0, StrgWhlAngLmtHSC4:0, StrgWhlAngGrdLmtHSC4:0, PaddingGap16_1:0, RdFrictionCoefficientHSC4:0]
    C_RECORD_VCUStatus6: value-spec=fields=[WhlGndVelRNonDrvnV_HSC4:0, PaddingGap8_1:0, PaddingGap16_2:0, WhlGndVelRNonDrvn_HSC4:0, WhlGndVelLNonDrvn_HSC4:0, WhlGndVelLNonDrvnV_HSC4:0, PaddingGap8_3:0, PaddingGap16_4:0, WhlGndVelRDrvn_HSC4:0, WhlGndVelRDrvnV_HSC4:0, PaddingGap8_5:0, PaddingGap16_6:0, WhlGndVelLDrvn_HSC4:0, WhlGndVelLDrvnV_HSC4:0, PaddingGap8_7:0, PaddingGap16_8:0]
    C_RECORD_VCUStatus7: value-spec=fields=[ACInCarTemHSC4:0, FuelLvlPcntVHSC4:0, PaddingGap8_1:0, PaddingGap16_2:0, FuelLvlPcntHSC4:0, AmbtLghtLvlHSC4:0, OtsdAirTemCrValV_HSC4:0, PaddingGap16_3:0, OtsdAirTemCrVal_HSC4:0, BrkLghtsStaHSC4:0, DangerousWrnngLghtStaHSC4:0, DipdBeamLampsStaHSC4:0, FrtFogLampStaHSC4:0, HornStaHSC4:0, LDircnLampsStaHSC4:0, MainBeamLampsStaHSC4:0, RDircnLampsStaHSC4:0, RevsngLghtStaHSC4:0, RrFogLampStaHSC4:0, WidthLampAndTaillightStateHSC4:0, WiperStaHSC4:0, WshrStaHSC4:0, PaddingGap8_4:0, PaddingGap16_5:0]
    C_RECORD_VCUStatus8: value-spec=fields=[TimeDspFmtHSC2:0, SecsOfMinuteHSC2:0, MinuteOfHourHSC2:0, HourOfDayHSC2:0, CalendarYearHSC5:0, CalendarMonthHSC2:0, CalendarDayHSC2:0, PaddingGap8_1:0]
    C_RECORD_VCUStatus9: value-spec=fields=[VCUMainID:0, VCUAddonsID:0, Vehicleplatform:0, VCUstage:0, Projectname:0, Component:0, PaddingGap16_1:0, VehOdoHSC2:0]
    C_RECORD_VCUStatusTest1: value-spec=fields=[Test4:0, Test3:0, Test2:0, Test1:0]
    C_RECORD_VCUStatusTest2: value-spec=fields=[Test8:0, Test7:0, Test6:0, Test5:0]
    C_RECORD_VCUStatusTest3: value-spec=fields=[Test12:0, Test11:0, Test10:0, Test9:0]
    C_RECORD_VCUStatusTest4: value-spec=fields=[Test16:0, Test15:0, Test14:0, Test13:0]
    C_RECORD_VCUVehicleInfo: value-spec=fields=[TimeStamp:0, FrameID:0, PaddingGap8_1:0, Counter:0, PaddingGap16_2:0, PaddingGap16_3:0, gb560:0, fSteeringAngle:0, fSpeed:0, fYawRate:0, fFrontLeftWheelSpeed:0, fFrontRightWheelSpeed:0, fRearLeftWheelSpeed:0, fRearRightWheelSpeed:0, nShifterPosition:0, nLeftDirectionLamp:0, nRightDirectionLamp:0, nMainBeamLamp:0, nDippedBeamLamp:0, nWiperState:0, PaddingGap16_4:0, fLateralAccel:0, fLongituAccel:0, nLeftDrivenWheelPulseCounters:0, nRightDrivenWheelPulseCounters:0, nLeftNonDrivenWheelPulseCounters:0, nRightnonDrivenWheelPulseCounters:0, nDriveMode:0, PaddingGap8_5:0, PaddingGap16_6:0]
    C_RECORD_VelNorthEast: value-spec=fields=[EastVelocitysecinfo:0, NorthVelocitysecinfo:0]
    C_RECORD_VelocityInfoRTK: value-spec=fields=[DownVelocityRTK:0, EastVelocityRTK:0, NorthVelocityRTK:0]
    C_RECORD_VelocitySigma: value-spec=fields=[Velnorthsigma:0, Veleastsigma:0, Veldownsigma:0]
    C_RECORD_VersionNumber: value-spec=fields=[ARMAPPVersecinfo:0, ARMBLVersecinfo:0, DSPAPPVersecinfo:0, DSPBLVersecinfo:0]
    C_RECORD_VMS_VMSSlave: value-spec=fields=[TimeStamp:0, FrameID:0, PaddingGap8_1:0, Counter:0, Counters:0, VehicleDriveModeSts:0, PaddingGap16_2:0, nReserved:0, PaddingGap16_3:0, PaddingGap16_4:0]
    C_RECORD_VMSSlave_VMS_100ms: value-spec=fields=[TimeStamp:0, FrameID:0, PaddingGap8_1:0, Counter:0, Counters:0, PaddingGap8_2:0, PaddingGap16_3:0, nReserved:0, PaddingGap16_4:0, PaddingGap16_5:0]
package /DataTypes
  125 x impl type, all with sw-calibration-access=READ-ONLY, type-emitter=RTE:
    Dt_ARRAY_10_sint16: category=ARRAY
      element Element: array-size=10, array-size-semantics=FIXED-SIZE, implementation-data-type=sint16
    Dt_ARRAY_10_uint32: category=ARRAY
      element Element: array-size=10, array-size-semantics=FIXED-SIZE, implementation-data-type=uint32
    Dt_ARRAY_10_uint8: category=ARRAY
      element Element: array-size=10, array-size-semantics=FIXED-SIZE, implementation-data-type=uint8
    Dt_ARRAY_100_float64: category=ARRAY
      element Element: array-size=100, array-size-semantics=FIXED-SIZE, implementation-data-type=float64
    Dt_ARRAY_20_RDA_Secinfo_FrP: category=ARRAY
      element Element: array-size=20, array-size-semantics=FIXED-SIZE, implementation-data-type=Dt_RECORD_RDA_Secinfo_FrP
    Dt_ARRAY_200_float32: category=ARRAY
      element Element: array-size=200, array-size-semantics=FIXED-SIZE, implementation-data-type=float32
    Dt_ARRAY_32_FSDA_FrP: category=ARRAY
      element Element: array-size=32, array-size-semantics=FIXED-SIZE, implementation-data-type=Dt_RECORD_FSDA_FrP
    Dt_ARRAY_32_RADAR_SecCH_FrP: category=ARRAY
      element Element: array-size=32, array-size-semantics=FIXED-SIZE, implementation-data-type=Dt_RECORD_RADAR_SecCH_FrP
    Dt_ARRAY_4_float64: category=ARRAY
      element Element: array-size=4, array-size-semantics=FIXED-SIZE, implementation-data-type=float64
    Dt_ARRAY_4_uint32: category=ARRAY
      element Element: array-size=4, array-size-semantics=FIXED-SIZE, implementation-data-type=uint32
    Dt_ARRAY_9_float64: category=ARRAY
      element Element: array-size=9, array-size-semantics=FIXED-SIZE, implementation-data-type=float64
    Dt_ARRAY_9_tag_reserve_double: category=ARRAY
      element Element: array-size=9, array-size-semantics=FIXED-SIZE, implementation-data-type=Dt_ARRAY_9_float64
    Dt_ARRAY_9_tag_reserve_int: category=ARRAY
      element Element: array-size=9, array-size-semantics=FIXED-SIZE, implementation-data-type=Dt_ARRAY_9_uint8
    Dt_ARRAY_9_uint8: category=ARRAY
      element Element: array-size=9, array-size-semantics=FIXED-SIZE, implementation-data-type=uint8
    Dt_RECORD_AccBias_Lcc: category=STRUCTURE
      4 x element, all with category=TYPE_REFERENCE, implementation-data-type=float32:
        AxBiassecinfo
        AyBiassecinfo
        AzBiassecinfo
        Lccsecinfo
    Dt_RECORD_Acce_AngularVel_X: category=STRUCTURE
      element AccelerationXsecinfo: implementation-data-type=float32
      element AngularRateXsecinfo: implementation-data-type=float32
    Dt_RECORD_Acce_AngularVel_Y: category=STRUCTURE
      element AccelerationYsecinfo: implementation-data-type=float32
      element AngularRateYsecinfo: implementation-data-type=float32
    Dt_RECORD_Acce_AngularVel_Z: category=STRUCTURE
      element AccelerationZsecinfo: implementation-data-type=float32
      element AngularRateZsecinfo: implementation-data-type=float32
    Dt_RECORD_AtterrStatus2: category=STRUCTURE
      6 x element, all with category=TYPE_REFERENCE, implementation-data-type=float32:
        PitchStdsecinfo
        RollStdsecinfo
        VelDStdsecinfo
        VelEStdsecinfo
        VelNStdsecinfo
        YawStdsecinfo
    Dt_RECORD_BaseInfoRTK: category=STRUCTURE
      element EastDistancRTK: implementation-data-type=float32
      element NorthDistancRTK: implementation-data-type=float32
    Dt_RECORD_CRD_att: category=STRUCTURE
      element roll: implementation-data-type=float32
      element pitch: implementation-data-type=float32
      element heading: implementation-data-type=float32
    Dt_RECORD_CRD_LLA: category=STRUCTURE
      element longitude: implementation-data-type=float64
      element latitude: implementation-data-type=float64
      element height: implementation-data-type=float64
    Dt_RECORD_CRD_NED: category=STRUCTURE
      element north: implementation-data-type=float32
      element east: implementation-data-type=float32
      element down: implementation-data-type=float32
    Dt_RECORD_CRD_XYZ_Float32: category=STRUCTURE
      element X: implementation-data-type=float32
      element Y: implementation-data-type=float32
      element Z: implementation-data-type=float32
    Dt_RECORD_CRD_XYZ_Float64: category=STRUCTURE
      element X: implementation-data-type=float64
      element Y: implementation-data-type=float64
      element Z: implementation-data-type=float64
    Dt_RECORD_Ctrl_IDCCAN_IDCStatus1: category=STRUCTURE
      11 x element, all with category=TYPE_REFERENCE:
        stHeader: implementation-data-type=Dt_RECORD_HEADER
        fStrgWhlAngReq_degHSC4: implementation-data-type=float32
        bEngToqReqVHSC4: implementation-data-type=boolean
        bStrgWhlAngGrdReqV_degpsHSC4: implementation-data-type=boolean
        bStrgWhlAngReqV_degHSC4: implementation-data-type=boolean
        bStrgWhlToqReqV_NmHSC4: implementation-data-type=boolean
        fEngToqReqHSC4: implementation-data-type=float32
        fStrgWhlAngGrdReq_degpsHSC4: implementation-data-type=float32
        fStrgWhlToqReq_NmHSC4: implementation-data-type=float32
        PaddingGap16_1: implementation-data-type=uint16
        PaddingGap16_2: implementation-data-type=uint16
    Dt_RECORD_Ctrl_IDCCAN_IDCStatus10: category=STRUCTURE
      5 x element, all with category=TYPE_REFERENCE:
        stHeader: implementation-data-type=Dt_RECORD_HEADER
        nRCar2AurixReserve100ms_{5..8}: implementation-data-type=sint16
    Dt_RECORD_Ctrl_IDCCAN_IDCStatus11: category=STRUCTURE
      5 x element, all with category=TYPE_REFERENCE:
        stHeader: implementation-data-type=Dt_RECORD_HEADER
        nRCar2AurixReserve100ms_{9..12}: implementation-data-type=sint16
    Dt_RECORD_Ctrl_IDCCAN_IDCStatus12: category=STRUCTURE
      5 x element, all with category=TYPE_REFERENCE:
        stHeader: implementation-data-type=Dt_RECORD_HEADER
        fRCar2AurixReserve100ms_{1..4}: implementation-data-type=float32
    Dt_RECORD_Ctrl_IDCCAN_IDCStatus13: category=STRUCTURE
      5 x element, all with category=TYPE_REFERENCE:
        stHeader: implementation-data-type=Dt_RECORD_HEADER
        fRCar2AurixReserve100ms_{5..8}: implementation-data-type=float32
    Dt_RECORD_Ctrl_IDCCAN_IDCStatus14: category=STRUCTURE
      5 x element, all with category=TYPE_REFERENCE:
        stHeader: implementation-data-type=Dt_RECORD_HEADER
        fRCar2AurixReserve100ms_{9..12}: implementation-data-type=float32
    Dt_RECORD_Ctrl_IDCCAN_IDCStatus15: category=STRUCTURE
      5 x element, all with category=TYPE_REFERENCE:
        stHeader: implementation-data-type=Dt_RECORD_HEADER
        fRCar2AurixReserve100ms_{13..16}: implementation-data-type=float32
    Dt_RECORD_Ctrl_IDCCAN_IDCStatus16: category=STRUCTURE
      5 x element, all with category=TYPE_REFERENCE:
        stHeader: implementation-data-type=Dt_RECORD_HEADER
        fRCar2AurixReserve100ms_{17..20}: implementation-data-type=float32
    Dt_RECORD_Ctrl_IDCCAN_IDCStatus17: category=STRUCTURE
      5 x element, all with category=TYPE_REFERENCE:
        stHeader: implementation-data-type=Dt_RECORD_HEADER
        fRCar2AurixReserve100ms_{21..24}: implementation-data-type=float32
    Dt_RECORD_Ctrl_IDCCAN_IDCStatus18: category=STRUCTURE
      5 x element, all with category=TYPE_REFERENCE:
        stHeader: implementation-data-type=Dt_RECORD_HEADER
        fRCar2AurixReserve100ms_{25..28}: implementation-data-type=float32
    Dt_RECORD_Ctrl_IDCCAN_IDCStatus19: category=STRUCTURE
      5 x element, all with category=TYPE_REFERENCE:
        stHeader: implementation-data-type=Dt_RECORD_HEADER
        fRCar2AurixReserve100ms_{29..32}: implementation-data-type=float32
    Dt_RECORD_Ctrl_IDCCAN_IDCStatus2: category=STRUCTURE
      16 x element, all with category=TYPE_REFERENCE:
        stHeader: implementation-data-type=Dt_RECORD_HEADER
        bDecAccReqV_mpssHSC4: implementation-data-type=boolean
        bDecPressureReqV_barHSC4: implementation-data-type=boolean
        bShifterPosReqVHSC4: implementation-data-type=boolean
        PaddingGap8_1: implementation-data-type=uint8
        fDecAccReq_mpssHSC4: implementation-data-type=float32
        fDecPressureReq_barHSC4: implementation-data-type=float32
        nEPBReqHSC4: implementation-data-type=uint8
        nRCarAlv10msRCHSC4: implementation-data-type=uint8
        nSCSDriverOffReqHSC4: implementation-data-type=uint8
        nSCSStandStillReqHSC4: implementation-data-type=uint8
        nShifterPosReqHSC4: implementation-data-type=uint8
        PaddingGap8_2: implementation-data-type=uint8
        PaddingGap16_{3..5}: implementation-data-type=uint16
    Dt_RECORD_Ctrl_IDCCAN_IDCStatus3: category=STRUCTURE
      5 x element, all with category=TYPE_REFERENCE:
        stHeader: implementation-data-type=Dt_RECORD_HEADER
        fRCar2AurixReserve30ms_{1..4}: implementation-data-type=float32
    Dt_RECORD_Ctrl_IDCCAN_IDCStatus4: category=STRUCTURE
      5 x element, all with category=TYPE_REFERENCE:
        stHeader: implementation-data-type=Dt_RECORD_HEADER
        nRCar2AurixReserve30ms_{1..4}: implementation-data-type=sint16
    Dt_RECORD_Ctrl_IDCCAN_IDCStatus5: category=STRUCTURE
      5 x element, all with category=TYPE_REFERENCE:
        stHeader: implementation-data-type=Dt_RECORD_HEADER
        fRCar2AurixReserve10ms_{1..4}: implementation-data-type=float32
    Dt_RECORD_Ctrl_IDCCAN_IDCStatus6: category=STRUCTURE
      5 x element, all with category=TYPE_REFERENCE:
        stHeader: implementation-data-type=Dt_RECORD_HEADER
        fRCar2AurixReserve10ms_{5..8}: implementation-data-type=float32
    Dt_RECORD_Ctrl_IDCCAN_IDCStatus7: category=STRUCTURE
      5 x element, all with category=TYPE_REFERENCE:
        stHeader: implementation-data-type=Dt_RECORD_HEADER
        nRCar2AurixReserve10ms_{1..4}: implementation-data-type=sint16
    Dt_RECORD_Ctrl_IDCCAN_IDCStatus9: category=STRUCTURE
      5 x element, all with category=TYPE_REFERENCE:
        stHeader: implementation-data-type=Dt_RECORD_HEADER
        nRCar2AurixReserve100ms_{1..4}: implementation-data-type=sint16
    Dt_RECORD_Diagnosticmessage: category=STRUCTURE
      11 x element, all with category=TYPE_REFERENCE:
        Rightsidequalityofantennasignal: implementation-data-type=uint8
        Leftsidequalityofantennasignal: implementation-data-type=uint8
        CANprotocolinternalversion: implementation-data-type=uint8
        GNSSReceiverstartupstatus: implementation-data-type=boolean
        AGNSSephemerisreceivedstatus: implementation-data-type=boolean
        CANdatasendstatus: implementation-data-type=boolean
        Mobilenetwork: implementation-data-type=boolean
        RightsideGNSSAntennastatus: implementation-data-type=uint8
        LeftsideGNSSAntennastatus: implementation-data-type=uint8
        PaddingGap8_1: implementation-data-type=uint8
        PaddingGap16_2: implementation-data-type=uint16
    Dt_RECORD_Diagnosticmessage_IMU: category=STRUCTURE
      4 x element, all with category=TYPE_REFERENCE, implementation-data-type=uint8:
        DiffDataLinkBrokensecinfo
        GNSSAntenasBrokensecinfo
        GPSMsgErrInIMUsecinfo
        IECUMsgErrInIMUsecinfo
    Dt_RECORD_ETC1: category=STRUCTURE
      13 x element, all with category=TYPE_REFERENCE:
        TransDrivelineEngaged: implementation-data-type=uint8
        TransTorqueConverterLockupEngag: implementation-data-type=uint8
        TransShiftlnProcess: implementation-data-type=uint8
        PaddingGap8_1: implementation-data-type=uint8
        TransOutputShaftSpeed: implementation-data-type=float32
        PercentClutchSlip: implementation-data-type=float32
        EngineMomentaryOverspeedEnable: implementation-data-type=uint8
        ProgressiveShiftDisable: implementation-data-type=uint8
        PaddingGap16_2: implementation-data-type=uint16
        TransInputShaftSpeed: implementation-data-type=float32
        SrcAddressCtrlDeviceForTransCtrl: implementation-data-type=uint8
        PaddingGap8_3: implementation-data-type=uint8
        PaddingGap16_4: implementation-data-type=uint16
    Dt_RECORD_FaultStatusMsg: category=STRUCTURE
      17 x element, all with category=TYPE_REFERENCE:
        stHeader: implementation-data-type=Dt_RECORD_HEADER
        FailureBitChassis: implementation-data-type=uint32
        FailureBitEyeQ4: implementation-data-type=uint32
        FailureBitIECU: implementation-data-type=uint32
        FailureBitLidar: implementation-data-type=uint32
        FailureBitAV: implementation-data-type=uint32
        FailureBitSV: implementation-data-type=uint32
        FailureBitCAN: implementation-data-type=uint32
        FailureBitLoc: implementation-data-type=uint32
        FailureBitIBOX: implementation-data-type=uint32
        FailureBitReserved_1: implementation-data-type=uint32
        FailureBitReserved: implementation-data-type=Dt_ARRAY_10_uint32
        Action: implementation-data-type=uint32
        FailureBitReserved_2: implementation-data-type=uint32
        Level: implementation-data-type=uint32
        PaddingGap16_1: implementation-data-type=uint16
        PaddingGap16_2: implementation-data-type=uint16
    Dt_RECORD_FSDA_FrP: category=STRUCTURE
      8 x element, all with category=TYPE_REFERENCE:
        FSDA_FrP_yspeed: implementation-data-type=float32
        FSDA_FrP_ypoint: implementation-data-type=float32
        FSDA_FrP_xspeed: implementation-data-type=float32
        FSDA_FrP_xpoint: implementation-data-type=float32
        FSDA_FrP_V: implementation-data-type=boolean
        FSDA_FrP_rollingcn: implementation-data-type=uint8
        FSDA_FrP_id: implementation-data-type=uint8
        PaddingGap8_1: implementation-data-type=uint8
    Dt_RECORD_GPS_ECUStatus: category=STRUCTURE
      10 x element, all with category=TYPE_REFERENCE:
        ECUWarningsecinfo: implementation-data-type=uint8
        GPSHeadingStatussecinfo: implementation-data-type=uint8
        GPSPosStatussecinfo: implementation-data-type=uint8
        PaddingGap8_1: implementation-data-type=uint8
        GPSStatussecinfo: implementation-data-type=uint16
        GPSVelStatussecinfo: implementation-data-type=uint8
        GPSWarningsecinfo: implementation-data-type=uint8
        RTKDelaysecinfo: implementation-data-type=uint8
        VehiclesStatussecinfo: implementation-data-type=uint8
        PaddingGap16_2: implementation-data-type=uint16
    Dt_RECORD_GPSPos_HeadingPrecison: category=STRUCTURE
      4 x element, all with category=TYPE_REFERENCE, implementation-data-type=float32:
        AltSigmaGPSsecinfo
        HeadingSigmaGPSsecinfo
        LatSigmaGPSsecinfo
        LonSigmaGPSsecinfo
    Dt_RECORD_GPSVel_PitchPrecison: category=STRUCTURE
      4 x element, all with category=TYPE_REFERENCE, implementation-data-type=float32:
        PitchSigmaGPSsecinfo
        VeldownsigmaGPSsecinfo
        VeleastsigmaGPSsecinfo
        VelnorthsigmaGPSsecinfo
    Dt_RECORD_GyroBias_Kws: category=STRUCTURE
      4 x element, all with category=TYPE_REFERENCE, implementation-data-type=float32:
        GxBiassecinfo
        GyBiassecinfo
        GzBiassecinfo
        Kwssecinfo
    Dt_RECORD_HEADER: category=STRUCTURE
      6 x element, all with category=TYPE_REFERENCE:
        TimeStamp: implementation-data-type=float64
        FrameID: implementation-data-type=uint8
        status: implementation-data-type=uint8
        Counter: implementation-data-type=uint16
        PaddingGap16_1: implementation-data-type=uint16
        PaddingGap16_2: implementation-data-type=uint16
    Dt_RECORD_HeadingPitchInfoRTK: category=STRUCTURE
      4 x element, all with category=TYPE_REFERENCE, implementation-data-type=float32:
        PitchSigma
        HeadingSigma
        PitchRTK
        HeadingRTK
    Dt_RECORD_IDC2VMS_res1: category=STRUCTURE
      element stHeader: implementation-data-type=Dt_RECORD_HEADER
      element reserved_float64: implementation-data-type=Dt_ARRAY_100_float64
    Dt_RECORD_IDC2VMS_res2: category=STRUCTURE
      element stHeader: implementation-data-type=Dt_RECORD_HEADER
      element reserved_float64: implementation-data-type=Dt_ARRAY_100_float64
    Dt_RECORD_iECU_250h: category=STRUCTURE
      element SA_AngleValue: implementation-data-type=float32
    Dt_RECORD_iECU_255h: category=STRUCTURE
      7 x element, all with category=TYPE_REFERENCE:
        iECU_PEGSUS_pilotWarning: implementation-data-type=uint8
        iECU_PEGSUS_pilotStatus: implementation-data-type=uint8
        PaddingGap16_1: implementation-data-type=uint16
        iECU_pilotDisableInfo: implementation-data-type=uint32
        iECU_pilot_OverrideIndicator: implementation-data-type=boolean
        PaddingGap8_2: implementation-data-type=uint8
        PaddingGap16_3: implementation-data-type=uint16
    Dt_RECORD_iECU_256h: category=STRUCTURE
      element iECU_pilot_Steer_Override: implementation-data-type=boolean
      element PaddingGap8_1: implementation-data-type=uint8
      element PaddingGap16_2: implementation-data-type=uint16
    Dt_RECORD_iECU_25Ah: category=STRUCTURE
      element iECU_PEGSUS_AEBState: implementation-data-type=uint8
      element PaddingGap8_1: implementation-data-type=uint8
      element PaddingGap16_2: implementation-data-type=uint16
    Dt_RECORD_IECU_25Bh: category=STRUCTURE
      element LockandTwistSwitch: implementation-data-type=boolean
      element PaddingGap8_1: implementation-data-type=uint8
      element PaddingGap16_2: implementation-data-type=uint16
    Dt_RECORD_IECU_FMS1: category=STRUCTURE
      element HighResolutionTripDistance_FMS: implementation-data-type=uint32
      element HghRsolTotalVehDistance_FMS: implementation-data-type=uint32
    Dt_RECORD_IECU_FMS2: category=STRUCTURE
      element Byte7: implementation-data-type=uint32
      element ResidualLiquidLevel_FMS: implementation-data-type=uint16
      element PaddingGap16_1: implementation-data-type=uint16
    Dt_RECORD_IECU1toPegasus: category=STRUCTURE
      element FailureBitODFSIECU1: implementation-data-type=uint32
      element FailureBitActor01: implementation-data-type=uint32
    Dt_RECORD_IECUInternal: category=STRUCTURE
      element Byte3: implementation-data-type=uint32
      element FailureBitIECU1Internal: implementation-data-type=uint32
    Dt_RECORD_IMUinfo: category=STRUCTURE
      24 x element, all with category=TYPE_REFERENCE:
        Acce_AngularVel_X: implementation-data-type=Dt_RECORD_Acce_AngularVel_X
        Acce_AngularVel_Y: implementation-data-type=Dt_RECORD_Acce_AngularVel_Y
        Acce_AngularVel_Z: implementation-data-type=Dt_RECORD_Acce_AngularVel_Z
        AtterrStatus2: implementation-data-type=Dt_RECORD_AtterrStatus2
        INSAltitude_VelDown: implementation-data-type=Dt_RECORD_INSAltitude_VelDown
        INSLatitudeInfo: implementation-data-type=Dt_RECORD_INSLatitudeInfo
        INSLongitudeInfo: implementation-data-type=Dt_RECORD_INSLongitudeInfo
        NavStatus_Heading: implementation-data-type=Dt_RECORD_NavStatus_Heading
        Pitch_Roll: implementation-data-type=Dt_RECORD_Pitch_Roll
        PoserrStatus1: implementation-data-type=Dt_RECORD_PoserrStatus1
        StatusInfo: implementation-data-type=Dt_RECORD_StatusInfo
        VelNorthEast: implementation-data-type=Dt_RECORD_VelNorthEast
        AccBias_Lcc: implementation-data-type=Dt_RECORD_AccBias_Lcc
        GPS_ECUStatus: implementation-data-type=Dt_RECORD_GPS_ECUStatus
        GPSPos_HeadingPrecison: implementation-data-type=Dt_RECORD_GPSPos_HeadingPrecison
        GPSVel_PitchPrecison: implementation-data-type=Dt_RECORD_GPSVel_PitchPrecison
        GyroBias_Kws: implementation-data-type=Dt_RECORD_GyroBias_Kws
        INSATB: implementation-data-type=Dt_RECORD_INSATB
        INSATG: implementation-data-type=Dt_RECORD_INSATG
        INSLTC_LTG: implementation-data-type=Dt_RECORD_INSLTC_LTG
        VersionNumber: implementation-data-type=Dt_RECORD_VersionNumber
        Diagnosticmessage_IMU: implementation-data-type=Dt_RECORD_Diagnosticmessage_IMU
        INSTIme: implementation-data-type=Dt_RECORD_INSTIme
        ReservedMsg: implementation-data-type=Dt_RECORD_ReservedMsg
    Dt_RECORD_INSAltitude_VelDown: category=STRUCTURE
      element AltitudeINSsecinfo: implementation-data-type=float32
      element DownVelocitysecinfo: implementation-data-type=float32
    Dt_RECORD_INSATB: category=STRUCTURE
      element ATB_pitchsecinfo: implementation-data-type=float32
      element ATB_rollsecinfo: implementation-data-type=float32
      element ATB_yawsecinfo: implementation-data-type=float32
    Dt_RECORD_INSATG: category=STRUCTURE
      element ATG_pitchsecinfo: implementation-data-type=float32
      element ATG_rollsecinfo: implementation-data-type=float32
      element ATG_yawsecinfo: implementation-data-type=float32
    Dt_RECORD_INSLatitudeInfo: category=STRUCTURE
      element LatitudeINSsecinfo: implementation-data-type=float64
    Dt_RECORD_INSLongitudeInfo: category=STRUCTURE
      element LongitudeINSsecinfo: implementation-data-type=float64
    Dt_RECORD_INSLTC_LTG: category=STRUCTURE
      6 x element, all with category=TYPE_REFERENCE, implementation-data-type=float32:
        LTC_xsecinfo
        LTC_ysecinfo
        LTC_zsecinfo
        LTG_xsecinfo
        LTG_ysecinfo
        LTG_zsecinfo
    Dt_RECORD_INSTIme: category=STRUCTURE
      element UTCTime_YDM: implementation-data-type=uint32
      element UTCTime_HMSssss_IMU: implementation-data-type=uint32
    Dt_RECORD_IntegratedPositioning_ToVMS: category=STRUCTURE
      53 x element, all with category=TYPE_REFERENCE:
        stHeader: implementation-data-type=Dt_RECORD_HEADER
        time_sec: implementation-data-type=float64
        data_name: implementation-data-type=uint8
        valid: implementation-data-type=uint8
        PaddingGap16_1: implementation-data-type=uint16
        weight: implementation-data-type=float32
        pos_real: implementation-data-type=Dt_RECORD_CRD_LLA
        pos_utm_real: implementation-data-type=Dt_RECORD_CRD_XYZ_Float64
        pos_Encryption: implementation-data-type=Dt_RECORD_CRD_LLA
        pos_utm_Encryption: implementation-data-type=Dt_RECORD_CRD_XYZ_Float64
        vel: implementation-data-type=Dt_RECORD_CRD_NED
        att: implementation-data-type=Dt_RECORD_CRD_att
        heading_reverse: implementation-data-type=float64
        heading_reverse_flag: implementation-data-type=uint8
        PaddingGap8_2: implementation-data-type=uint8
        PaddingGap16_3: implementation-data-type=uint16
        cal_line_acc: implementation-data-type=Dt_RECORD_CRD_XYZ_Float32
        cal_line_anglerate: implementation-data-type=Dt_RECORD_CRD_XYZ_Float32
        PaddingGap16_4: implementation-data-type=uint16
        PaddingGap16_5: implementation-data-type=uint16
        lasttime_sec: implementation-data-type=float64
        deltaime: implementation-data-type=float32
        PaddingGap16_6: implementation-data-type=uint16
        PaddingGap16_7: implementation-data-type=uint16
        delta_pos_deg: implementation-data-type=Dt_RECORD_CRD_LLA
        delta_pos_XYZ: implementation-data-type=Dt_RECORD_CRD_XYZ_Float32
        delta_vel_m_s: implementation-data-type=Dt_RECORD_CRD_NED
        delta_att_rad: implementation-data-type=Dt_RECORD_CRD_att
        PaddingGap16_8: implementation-data-type=uint16
        PaddingGap16_9: implementation-data-type=uint16
        tag_reserve_double: implementation-data-type=Dt_ARRAY_9_tag_reserve_double
        tag_reserve_int: implementation-data-type=Dt_ARRAY_9_tag_reserve_int
        sensor_qosstate: implementation-data-type=uint8
        couple_flag: implementation-data-type=uint8
        reset_flag: implementation-data-type=uint8
        sensor_originaldata_qosstate: implementation-data-type=uint8
        sensor_dataflowstate: implementation-data-type=uint8
        crd_def: implementation-data-type=uint8
        hasbeenusedinkf_flag: implementation-data-type=uint8
        iIntegratedPositionMode: implementation-data-type=uint8
        iIntegratedVelMode: implementation-data-type=uint8
        iIntegratedOrientationMode: implementation-data-type=uint8
        bInitStatusPosition: implementation-data-type=uint8
        bInitStatusVel: implementation-data-type=uint8
        bInitStatusRP: implementation-data-type=uint8
        bInitStatusH: implementation-data-type=uint8
        pos_valid: implementation-data-type=uint8
        vel_valid: implementation-data-type=uint8
        att_valid: implementation-data-type=uint8
        PaddingGap16_{10..12}: implementation-data-type=uint16
        gpstime_sec: implementation-data-type=float64
    Dt_RECORD_LatitudeInfoRTK: category=STRUCTURE
      4 x element, all with category=TYPE_REFERENCE:
        UTCTime_YMD: implementation-data-type=uint32
        PaddingGap16_1: implementation-data-type=uint16
        PaddingGap16_2: implementation-data-type=uint16
        LatitudeRTK: implementation-data-type=float64
    Dt_RECORD_LongitudeInfoRTK: category=STRUCTURE
      4 x element, all with category=TYPE_REFERENCE:
        AltitudeRTK: implementation-data-type=float32
        PaddingGap16_1: implementation-data-type=uint16
        PaddingGap16_2: implementation-data-type=uint16
        LongitudeRTK: implementation-data-type=float64
    Dt_RECORD_MasterSlaveRTK: category=STRUCTURE
      7 x element, all with category=TYPE_REFERENCE:
        PositionAttitudeStatus: implementation-data-type=uint8
        DiffAgeInfo: implementation-data-type=uint8
        DiffBaseIDInfo: implementation-data-type=uint16
        Baselinelength: implementation-data-type=float32
        SatNoInAttitudeRTK: implementation-data-type=uint8
        SatNoInPositionRTK: implementation-data-type=uint8
        PaddingGap16_1: implementation-data-type=uint16
    Dt_RECORD_NavStatus_Heading: category=STRUCTURE
      7 x element, all with category=TYPE_REFERENCE:
        ChannelInfosecinfo: implementation-data-type=uint8
        PaddingGap8_1: implementation-data-type=uint8
        CurrentGPSTimesecinfo: implementation-data-type=uint16
        Headingsecinfo: implementation-data-type=float32
        NavStatussecinfo: implementation-data-type=uint8
        PaddingGap8_2: implementation-data-type=uint8
        PaddingGap16_3: implementation-data-type=uint16
    Dt_RECORD_Pitch_Roll: category=STRUCTURE
      element Pitchsecinfo: implementation-data-type=float32
      element Rollsecinfo: implementation-data-type=float32
    Dt_RECORD_PoserrStatus1: category=STRUCTURE
      element AltStdsecinfo: implementation-data-type=float32
      element LatStdsecinfo: implementation-data-type=float32
      element LonStdsecinfo: implementation-data-type=float32
    Dt_RECORD_PositionInfoRTK: category=STRUCTURE
      element UTCTime_HMSssss_RTK: implementation-data-type=uint32
      element SerialNumberRTK: implementation-data-type=uint32
    Dt_RECORD_PositionSigma: category=STRUCTURE
      element AltSigma: implementation-data-type=float32
      element LonSigma: implementation-data-type=float32
      element LatSigma: implementation-data-type=float32
    Dt_RECORD_Proto_IDC2VMS: category=STRUCTURE
      152 x element, all with category=TYPE_REFERENCE:
        TimeStamp: implementation-data-type=float64
        Counter: implementation-data-type=uint16
        IDCReady: implementation-data-type=boolean
        PaddingGap8_1: implementation-data-type=uint8
        IDCDTC: implementation-data-type=uint16
        IDC2VMSPV: implementation-data-type=uint16
        NoTechniqueTakeOverValid: implementation-data-type=boolean
        TaskStage: implementation-data-type=uint8
        PaddingGap16_{2..4}: implementation-data-type=uint16
        IDCBehavior: implementation-data-type=float64
        AdpStatus: implementation-data-type=uint8
        PaddingGap8_5: implementation-data-type=uint8
        PaddingGap16_6: implementation-data-type=uint16
        TrackCoefficiantX1: implementation-data-type=float32
        TrackCoefficiantX1V: implementation-data-type=boolean
        PaddingGap8_7: implementation-data-type=uint8
        PaddingGap16_8: implementation-data-type=uint16
        TrackCoefficiantX2: implementation-data-type=float32
        TrackCoefficiantX2V: implementation-data-type=boolean
        PaddingGap8_9: implementation-data-type=uint8
        PaddingGap16_10: implementation-data-type=uint16
        TrackCoefficiantX3: implementation-data-type=float32
        TrackCoefficiantX3V: implementation-data-type=boolean
        PaddingGap8_11: implementation-data-type=uint8
        PaddingGap16_12: implementation-data-type=uint16
        TrackCoefficiantX4: implementation-data-type=float32
        TrackCoefficiantX4V: implementation-data-type=boolean
        PaddingGap8_13: implementation-data-type=uint8
        PaddingGap16_14: implementation-data-type=uint16
        TrackCoefficiantX5: implementation-data-type=float32
        TrackCoefficiantX5V: implementation-data-type=boolean
        PaddingGap8_15: implementation-data-type=uint8
        PaddingGap16_16: implementation-data-type=uint16
        TrackCoefficiantY1: implementation-data-type=float32
        TrackCoefficiantY1V: implementation-data-type=boolean
        PaddingGap8_17: implementation-data-type=uint8
        PaddingGap16_18: implementation-data-type=uint16
        TrackCoefficiantY2: implementation-data-type=float32
        TrackCoefficiantY2V: implementation-data-type=boolean
        PaddingGap8_19: implementation-data-type=uint8
        PaddingGap16_20: implementation-data-type=uint16
        TrackCoefficiantY3: implementation-data-type=float32
        TrackCoefficiantY3V: implementation-data-type=boolean
        PaddingGap8_21: implementation-data-type=uint8
        PaddingGap16_22: implementation-data-type=uint16
        TrackCoefficiantY4: implementation-data-type=float32
        TrackCoefficiantY4V: implementation-data-type=boolean
        PaddingGap8_23: implementation-data-type=uint8
        PaddingGap16_24: implementation-data-type=uint16
        TrackCoefficiantY5: implementation-data-type=float32
        TrackCoefficiantY5V: implementation-data-type=boolean
        PaddingGap8_25: implementation-data-type=uint8
        PaddingGap16_26: implementation-data-type=uint16
        PathLength: implementation-data-type=float32
        TrackCoefficiantX1_Global: implementation-data-type=float32
        TrackCoefficiantX1V_Global: implementation-data-type=boolean
        PaddingGap8_27: implementation-data-type=uint8
        PaddingGap16_28: implementation-data-type=uint16
        TrackCoefficiantX2_Global: implementation-data-type=float32
        TrackCoefficiantX2V_Global: implementation-data-type=boolean
        PaddingGap8_29: implementation-data-type=uint8
        PaddingGap16_30: implementation-data-type=uint16
        TrackCoefficiantX3_Global: implementation-data-type=float32
        TrackCoefficiantX3V_Global: implementation-data-type=boolean
        PaddingGap8_31: implementation-data-type=uint8
        PaddingGap16_32: implementation-data-type=uint16
        TrackCoefficiantX4_Global: implementation-data-type=float32
        TrackCoefficiantX4V_Global: implementation-data-type=boolean
        PaddingGap8_33: implementation-data-type=uint8
        PaddingGap16_34: implementation-data-type=uint16
        TrackCoefficiantX5_Global: implementation-data-type=float32
        TrackCoefficiantX5V_Global: implementation-data-type=boolean
        PaddingGap8_35: implementation-data-type=uint8
        PaddingGap16_36: implementation-data-type=uint16
        TrackCoefficiantY1_Global: implementation-data-type=float32
        TrackCoefficiantY1V_Global: implementation-data-type=boolean
        PaddingGap8_37: implementation-data-type=uint8
        PaddingGap16_38: implementation-data-type=uint16
        TrackCoefficiantY2_Global: implementation-data-type=float32
        TrackCoefficiantY2V_Global: implementation-data-type=boolean
        PaddingGap8_39: implementation-data-type=uint8
        PaddingGap16_40: implementation-data-type=uint16
        TrackCoefficiantY3_Global: implementation-data-type=float32
        TrackCoefficiantY3V_Global: implementation-data-type=boolean
        PaddingGap8_41: implementation-data-type=uint8
        PaddingGap16_42: implementation-data-type=uint16
        TrackCoefficiantY4_Global: implementation-data-type=float32
        TrackCoefficiantY4V_Global: implementation-data-type=boolean
        PaddingGap8_43: implementation-data-type=uint8
        PaddingGap16_44: implementation-data-type=uint16
        TrackCoefficiantY5_Global: implementation-data-type=float32
        TrackCoefficiantY5V_Global: implementation-data-type=boolean
        PaddingGap8_45: implementation-data-type=uint8
        PaddingGap16_46: implementation-data-type=uint16
        PathLength_Global: implementation-data-type=float32
        RoadFollowError: implementation-data-type=float32
        FrontRoadFollowError: implementation-data-type=float32
        HeadingFollowError: implementation-data-type=float32
        PathRadiumMin: implementation-data-type=float32
        PathRadiumAvg: implementation-data-type=float32
        RounterChange: implementation-data-type=boolean
        SteeringWheelAngleCmdValid: implementation-data-type=boolean
        PaddingGap16_47: implementation-data-type=uint16
        SteeringWheelAngleCmd: implementation-data-type=float32
        SteeringWheelAngleGrdCmd: implementation-data-type=float32
        IsParkInTaskStage: implementation-data-type=boolean
        PaddingGap8_48: implementation-data-type=uint8
        PaddingGap16_49: implementation-data-type=uint16
        ParkLotTopPointY: implementation-data-type=float32
        ParkLotTopPointX: implementation-data-type=float32
        ParkLotAngleError: implementation-data-type=float32
        TrailerAngle: implementation-data-type=float32
        TrailerRoadFollowError: implementation-data-type=float64
        IsStraightLineControlMode: implementation-data-type=boolean
        ChangeLaneMode: implementation-data-type=uint8
        ReverseMode: implementation-data-type=boolean
        PaddingGap8_50: implementation-data-type=uint8
        LaneWidth: implementation-data-type=float32
        VehicleSpeedMaxLimit: implementation-data-type=float32
        LongitudinalAccRequest: implementation-data-type=float32
        VehicleSpeedRequest: implementation-data-type=float32
        ShiferPoseRequest: implementation-data-type=uint8
        PaddingGap8_51: implementation-data-type=uint8
        PaddingGap16_52: implementation-data-type=uint16
        DistanceToStop: implementation-data-type=float32
        IDCDriveEnvironment: implementation-data-type=uint8
        BrakeMode: implementation-data-type=uint8
        DippedBeamLampCmd: implementation-data-type=boolean
        MainBeamLampCmd: implementation-data-type=boolean
        LeftDirectionLampCmd: implementation-data-type=boolean
        RightDirectionLampCmd: implementation-data-type=boolean
        HornCmd: implementation-data-type=boolean
        WiperCmd: implementation-data-type=uint8
        PaddingGap16_53: implementation-data-type=uint16
        PaddingGap16_54: implementation-data-type=uint16
        Longitude: implementation-data-type=float64
        Latitude: implementation-data-type=float64
        Altitude: implementation-data-type=float64
        Heading: implementation-data-type=float64
        Pitch: implementation-data-type=float32
        Roll: implementation-data-type=float32
        LongitudinalAcc: implementation-data-type=float32
        LateralAcc: implementation-data-type=float32
        YawRate: implementation-data-type=float32
        Reserved_uint8: implementation-data-type=Dt_ARRAY_10_uint8
        Reserved_sint16: implementation-data-type=Dt_ARRAY_10_sint16
        PaddingGap16_55: implementation-data-type=uint16
        Reserved_float32: implementation-data-type=Dt_ARRAY_200_float32
        PaddingGap16_56: implementation-data-type=uint16
        PaddingGap16_57: implementation-data-type=uint16
    Dt_RECORD_RADAR_SecCH_FrP: category=STRUCTURE
      12 x element, all with category=TYPE_REFERENCE:
        RADAR_SecCH_FrP_ID: implementation-data-type=uint8
        PaddingGap8_1: implementation-data-type=uint8
        PaddingGap16_2: implementation-data-type=uint16
        RADAR_SecCH_FrP_dy: implementation-data-type=float32
        RADAR_SecCH_FrP_Vy: implementation-data-type=float32
        RADAR_SecCH_FrP_dx: implementation-data-type=float32
        RADAR_SecCH_FrP_Vx: implementation-data-type=float32
        RADAR_SecCH_FrP_SyncCtr: implementation-data-type=uint8
        PaddingGap8_3: implementation-data-type=uint8
        PaddingGap16_4: implementation-data-type=uint16
        RADAR_SecCH_FrP_wExist: implementation-data-type=float32
        RADAR_SecCH_FrP_wObstacle: implementation-data-type=float32
    Dt_RECORD_RADAR_SecCH_FrP32: category=STRUCTURE
      8 x element, all with category=TYPE_REFERENCE:
        AlignmentFail_SGUSecHS2: implementation-data-type=boolean
        HWFail_SGUSecHS2: implementation-data-type=boolean
        OtherFail_SGUSecHS2: implementation-data-type=boolean
        Sensor_Dirty_SGUSecHS2: implementation-data-type=boolean
        SGUFailSecHS2: implementation-data-type=boolean
        SGUObsDataSyncCtrSecHS2: implementation-data-type=uint8
        PaddingGap16_1: implementation-data-type=uint16
        SGUObsDataTmspSecHS2: implementation-data-type=float32
    Dt_RECORD_RADAR_SecCH_FrP33: category=STRUCTURE
      12 x element, all with category=TYPE_REFERENCE:
        AlignmentFail_TGUSecHS2: implementation-data-type=boolean
        FCWASecHS2: implementation-data-type=boolean
        PaddingGap16_1: implementation-data-type=uint16
        FCWTimeToColSecHS2: implementation-data-type=float32
        HWFail_TGUSecHS2: implementation-data-type=boolean
        ObsDataSyncCtrSecHS2: implementation-data-type=uint8
        PaddingGap16_2: implementation-data-type=uint16
        ObsDataTmspSecHS2: implementation-data-type=float32
        OtherFail_TGUSecHS2: implementation-data-type=boolean
        PedtrnColWrnngASecHS2: implementation-data-type=boolean
        Sensor_Dirty_TGUSecHS2: implementation-data-type=boolean
        TGUFailSecHS2: implementation-data-type=boolean
    Dt_RECORD_RADAR_SecCH_FrP34: category=STRUCTURE
      13 x element, all with category=TYPE_REFERENCE:
        DngrsObjExistSecHS2: implementation-data-type=float32
        DngrsObjId_PSecHS2: implementation-data-type=uint8
        PaddingGap8_1: implementation-data-type=uint8
        PaddingGap16_2: implementation-data-type=uint16
        DngrsObjObstacleSecHS2: implementation-data-type=float32
        DngrsObjSyncCtr_PSecHS2: implementation-data-type=uint8
        PaddingGap8_3: implementation-data-type=uint8
        PaddingGap16_4: implementation-data-type=uint16
        DngrsPedExistSecHS2: implementation-data-type=float32
        DngrsPedObstacleSecHS2: implementation-data-type=float32
        DngrsPedtrnId_PSecHS2: implementation-data-type=uint8
        DngrsPedtrnSyncCtr_PSecHS2: implementation-data-type=uint8
        PaddingGap16_5: implementation-data-type=uint16
    Dt_RECORD_RDA_HSC4_P01: category=STRUCTURE
      4 x element, all with category=TYPE_REFERENCE, implementation-data-type=uint8:
        BSDSelStssecinfo
        LCASelStssecinfo
        RDASwStssecinfo
        PaddingGap8_1
    Dt_RECORD_RDA_HSC4_S00: category=STRUCTURE
      element wake_network_RDAsecinfo: implementation-data-type=boolean
      element PaddingGap8_1: implementation-data-type=uint8
      element PaddingGap16_2: implementation-data-type=uint16
    Dt_RECORD_RDA_Secinfo_FrP: category=STRUCTURE
      7 x element, all with category=TYPE_REFERENCE:
        RDA_ttgt1V_secinfo: implementation-data-type=boolean
        RDA_ttgt1_id_secinfo: implementation-data-type=uint8
        PaddingGap16_1: implementation-data-type=uint16
        RDA_ttgt1_xpoint_secinfo: implementation-data-type=float32
        RDA_ttgt1_xspeed_secinfo: implementation-data-type=float32
        RDA_ttgt1_ypoint_secinfo: implementation-data-type=float32
        RDA_ttgt1_yspeed_secinfo: implementation-data-type=float32
    Dt_RECORD_RDA_Secinfo_HSC4_FrP00: category=STRUCTURE
      element keep_network_RDAsecinfo: implementation-data-type=boolean
      element PaddingGap8_1: implementation-data-type=uint8
      element PaddingGap16_2: implementation-data-type=uint16
    Dt_RECORD_RDA_Secinfo_HSC4_FrP02: category=STRUCTURE
      11 x element, all with category=TYPE_REFERENCE:
        DOWSelStssecinfo: implementation-data-type=uint8
        LBSDAndLCAWrnngsecinfo: implementation-data-type=uint8
        LDOWWrnngsecinfo: implementation-data-type=uint8
        LRCTAWrnngsecinfo: implementation-data-type=uint8
        RBSDAndLCAWrnngsecinfo: implementation-data-type=uint8
        RCTASelStssecinfo: implementation-data-type=uint8
        RDASysStasecinfo: implementation-data-type=uint8
        RDOWWrnngsecinfo: implementation-data-type=uint8
        RRCTAWrnngsecinfo: implementation-data-type=uint8
        PaddingGap8_1: implementation-data-type=uint8
        PaddingGap16_2: implementation-data-type=uint16
    Dt_RECORD_ReservedMsg: category=STRUCTURE
      element arrayuint32: implementation-data-type=Dt_ARRAY_4_uint32
      element arrayfloat64: implementation-data-type=Dt_ARRAY_4_float64
    Dt_RECORD_RTKinfo: category=STRUCTURE
      13 x element, all with category=TYPE_REFERENCE:
        BaseInfoRTK: implementation-data-type=Dt_RECORD_BaseInfoRTK
        Diagnosticmessage: implementation-data-type=Dt_RECORD_Diagnosticmessage
        HeadingPitchInfoRTK: implementation-data-type=Dt_RECORD_HeadingPitchInfoRTK
        PaddingGap16_1: implementation-data-type=uint16
        PaddingGap16_2: implementation-data-type=uint16
        LatitudeInfoRTK: implementation-data-type=Dt_RECORD_LatitudeInfoRTK
        LongitudeInfoRTK: implementation-data-type=Dt_RECORD_LongitudeInfoRTK
        MasterSlaveRTK: implementation-data-type=Dt_RECORD_MasterSlaveRTK
        PositionInfoRTK: implementation-data-type=Dt_RECORD_PositionInfoRTK
        PositionSigma: implementation-data-type=Dt_RECORD_PositionSigma
        VelocityInfoRTK: implementation-data-type=Dt_RECORD_VelocityInfoRTK
        VelocitySigma: implementation-data-type=Dt_RECORD_VelocitySigma
        ReservedMsg: implementation-data-type=Dt_RECORD_ReservedMsg
    Dt_RECORD_StatusInfo: category=STRUCTURE
      7 x element, all with category=TYPE_REFERENCE:
        ECUDelaysecinfo: implementation-data-type=uint8
        ECUFreqsecinfo: implementation-data-type=uint8
        GPSDelaysecinfo: implementation-data-type=uint8
        GPSFreqsecinfo: implementation-data-type=uint8
        INSDelaysecinfo: implementation-data-type=uint16
        INSStatussecinfo: implementation-data-type=uint8
        INSWarningsecinfo: implementation-data-type=uint8
    Dt_RECORD_SunRainSts: category=STRUCTURE
      4 x element, all with category=TYPE_REFERENCE:
        SunSts: implementation-data-type=boolean
        RainSts: implementation-data-type=boolean
        res_uint16: implementation-data-type=uint16
        res_uint32: implementation-data-type=uint32
    Dt_RECORD_UWB_EN_CMD: category=STRUCTURE
      6 x element, all with category=TYPE_REFERENCE:
        UWBLocEnCmdFlag: implementation-data-type=uint8
        PaddingGap8_1: implementation-data-type=uint8
        UWBLocEnAreaNo: implementation-data-type=uint16
        UWBLocEnAreaAttr: implementation-data-type=uint8
        UWBLocEn: implementation-data-type=boolean
        PaddingGap16_2: implementation-data-type=uint16
    Dt_RECORD_UWB_LOC: category=STRUCTURE
      12 x element, all with category=TYPE_REFERENCE:
        UWBLocAreaNo: implementation-data-type=uint16
        UWBLocAreaAttr: implementation-data-type=uint8
        PaddingGap8_1: implementation-data-type=uint8
        UWBLocY: implementation-data-type=sint16
        UWBLocX: implementation-data-type=sint16
        UWBLocCredit: implementation-data-type=uint8
        UWBLocXUnit: implementation-data-type=uint8
        UWBLocYUnit: implementation-data-type=uint8
        UWBLocType: implementation-data-type=uint8
        UWBLocRollingCounter: implementation-data-type=uint8
        PaddingGap8_2: implementation-data-type=uint8
        PaddingGap16_3: implementation-data-type=uint16
    Dt_RECORD_UWB_STATUS: category=STRUCTURE
      20 x element, all with category=TYPE_REFERENCE:
        UWBLocExptTimes: implementation-data-type=uint8
        UWBLocFailTimes: implementation-data-type=uint8
        UWBAchRxTimes: implementation-data-type=uint8
        UWBAchTxTimes: implementation-data-type=uint8
        UWBUwbRxTimes: implementation-data-type=uint8
        UWBUwbTxTimes: implementation-data-type=uint8
        UWBHwStatas6vTemp: implementation-data-type=uint8
        UWBHwStatas5v2v5: implementation-data-type=uint8
        UWBHwStatas3v3: implementation-data-type=uint8
        UWBHwStatas1v2: implementation-data-type=uint8
        UWBRfStatus: implementation-data-type=boolean
        UWBDsaStatus: implementation-data-type=boolean
        UWBLogicStatus: implementation-data-type=boolean
        UWBAchStatus: implementation-data-type=boolean
        UWBHwStatusType: implementation-data-type=boolean
        UWBLocEnErrFlg: implementation-data-type=boolean
        UWBLocEnStep: implementation-data-type=boolean
        UWBLocEnStatus: implementation-data-type=boolean
        UWBStatusHeader: implementation-data-type=uint8
        UWBTagType: implementation-data-type=uint8
    Dt_RECORD_UWBinfo: category=STRUCTURE
      element UWB_LOC: implementation-data-type=Dt_RECORD_UWB_LOC
      element UWB_STATUS: implementation-data-type=Dt_RECORD_UWB_STATUS
    Dt_RECORD_VCUStatus: category=STRUCTURE
      14 x element, all with category=TYPE_REFERENCE:
        stHeader: implementation-data-type=Dt_RECORD_HEADER
        ETC1: implementation-data-type=Dt_RECORD_ETC1
        VCUStatus1: implementation-data-type=Dt_RECORD_VCUStatus1
        VCUStatus2: implementation-data-type=Dt_RECORD_VCUStatus2
        VCUStatus8: implementation-data-type=Dt_RECORD_VCUStatus8
        VCUStatus10: implementation-data-type=Dt_RECORD_VCUStatus10
        VCUStatusTest{1..4}: implementation-data-type=Dt_RECORD_VCUStatusTest{1..4}
        iECU_250h: implementation-data-type=Dt_RECORD_iECU_250h
        VCUStatus9: implementation-data-type=Dt_RECORD_VCUStatus9
        PaddingGap16_1: implementation-data-type=uint16
        PaddingGap16_2: implementation-data-type=uint16
    Dt_RECORD_VCUStatus_reserved: category=STRUCTURE
      7 x element, all with category=TYPE_REFERENCE:
        IECU_FMS1: implementation-data-type=Dt_RECORD_IECU_FMS1
        IECU_FMS2: implementation-data-type=Dt_RECORD_IECU_FMS2
        IECU1toPegasus: implementation-data-type=Dt_RECORD_IECU1toPegasus
        IECUInternal: implementation-data-type=Dt_RECORD_IECUInternal
        VCUStatus_reserved5: implementation-data-type=Dt_RECORD_VCUStatus_reserved5
        VCUStatus_reserved6: implementation-data-type=Dt_RECORD_VCUStatus_reserved6
        ReservedMsg: implementation-data-type=Dt_RECORD_ReservedMsg
    Dt_RECORD_VCUStatus_reserved5: category=STRUCTURE
      element Byte9: implementation-data-type=uint32
      element Byte8: implementation-data-type=uint32
    Dt_RECORD_VCUStatus_reserved6: category=STRUCTURE
      element Byte11: implementation-data-type=uint32
      element Byte10: implementation-data-type=uint32
    Dt_RECORD_VCUStatus1: category=STRUCTURE
      11 x element, all with category=TYPE_REFERENCE:
        RouteComplete: implementation-data-type=boolean
        SCUShifterLvrPosHSC4: implementation-data-type=uint8
        PaddingGap16_1: implementation-data-type=uint16
        EPSMotOtptToqHSC4: implementation-data-type=float32
        PtBrkPdlDscrtInptStsVHSC4: implementation-data-type=boolean
        PtBrkPdlDscrtInptStsHSC4: implementation-data-type=boolean
        PaddingGap16_2: implementation-data-type=uint16
        EnSpdHSC4: implementation-data-type=float32
        DrivemModeStsHSC4: implementation-data-type=uint8
        DriveModeReqHSC4: implementation-data-type=boolean
        PaddingGap16_3: implementation-data-type=uint16
    Dt_RECORD_VCUStatus10: category=STRUCTURE
      12 x element, all with category=TYPE_REFERENCE:
        RNonDrvnWhlRotlDistVHSC2: implementation-data-type=boolean
        PaddingGap8_1: implementation-data-type=uint8
        RNonDrvnWhlRotlDistPCHSC2: implementation-data-type=uint16
        RDrvnWhlRotlDistVHSC2: implementation-data-type=boolean
        PaddingGap8_2: implementation-data-type=uint8
        RDrvnWhlRotlDistPlsCtrHSC2: implementation-data-type=uint16
        LDrvnWhlRotlDistVHSC2: implementation-data-type=boolean
        PaddingGap8_3: implementation-data-type=uint8
        LNonDrvnWhlRotlDistPCHSC2: implementation-data-type=uint16
        LNonDrvnWhlRotlDistVHSC2: implementation-data-type=boolean
        PaddingGap8_4: implementation-data-type=uint8
        LDrvnWhlRotlDistPlsCtrHSC2: implementation-data-type=uint16
    Dt_RECORD_VCUStatus2: category=STRUCTURE
      11 x element, all with category=TYPE_REFERENCE:
        StrgWhlAngHSC4: implementation-data-type=float32
        StrgWhlAngAlvRCHSC4: implementation-data-type=uint8
        PaddingGap8_1: implementation-data-type=uint8
        StrgWhlAngExtdPVHSC4: implementation-data-type=uint16
        StrgWhlAngGrdHSC4: implementation-data-type=sint16
        StrgWhlAngSnsrCalStsHSC4: implementation-data-type=uint8
        StrgWhlAngSnsrChksmHSC4: implementation-data-type=uint8
        StrgWhlAngSnsrFltHSC4: implementation-data-type=boolean
        StrgWhlAngSnsrInidHSC4: implementation-data-type=boolean
        StrgWhlAngSnsrMultCapbHSC4: implementation-data-type=boolean
        StrgWhlAngVHSC4: implementation-data-type=boolean
    Dt_RECORD_VCUStatus3: category=STRUCTURE
      16 x element, all with category=TYPE_REFERENCE:
        SysVol_HSC4: implementation-data-type=float32
        EPBAppcnStsHSC4: implementation-data-type=uint8
        VehSpdAvgVHSC4: implementation-data-type=boolean
        PaddingGap16_1: implementation-data-type=uint16
        VehSpdAvgHSC4: implementation-data-type=float32
        VSELongtAccVHSC4: implementation-data-type=boolean
        PaddingGap8_2: implementation-data-type=uint8
        PaddingGap16_3: implementation-data-type=uint16
        VSELongtAccHSC4: implementation-data-type=float32
        VehDynYawRateVHSC4: implementation-data-type=boolean
        PaddingGap8_4: implementation-data-type=uint8
        PaddingGap16_5: implementation-data-type=uint16
        VehDynYawRateHSC4: implementation-data-type=float32
        AirbagDplHSC4: implementation-data-type=boolean
        PaddingGap8_6: implementation-data-type=uint8
        PaddingGap16_7: implementation-data-type=uint16
    Dt_RECORD_VCUStatus4: category=STRUCTURE
      8 x element, all with category=TYPE_REFERENCE:
        VehLckngStaHSC4: implementation-data-type=boolean
        FrtPsngDoorOpenStsHSC4: implementation-data-type=uint8
        DrvrDoorOpenStsHSC4: implementation-data-type=uint8
        VehInertiaSwTrigdHSC4: implementation-data-type=boolean
        BrkPdlDrvrAppdPrsV_HSC4: implementation-data-type=boolean
        BrkPdlDrvrAppdPrsAlvRC_HSC4: implementation-data-type=uint8
        BrkPdlDrvrAppdPrs_HSC4: implementation-data-type=uint8
        PaddingGap8_1: implementation-data-type=uint8
    Dt_RECORD_VCUStatus5: category=STRUCTURE
      6 x element, all with category=TYPE_REFERENCE:
        VehDeceLmtHSC4: implementation-data-type=float32
        VehAcceLmtHSC4: implementation-data-type=float32
        StrgWhlAngLmtHSC4: implementation-data-type=float32
        StrgWhlAngGrdLmtHSC4: implementation-data-type=sint16
        PaddingGap16_1: implementation-data-type=uint16
        RdFrictionCoefficientHSC4: implementation-data-type=float32
    Dt_RECORD_VCUStatus6: category=STRUCTURE
      16 x element, all with category=TYPE_REFERENCE:
        WhlGndVelRNonDrvnV_HSC4: implementation-data-type=boolean
        PaddingGap8_1: implementation-data-type=uint8
        PaddingGap16_2: implementation-data-type=uint16
        WhlGndVelRNonDrvn_HSC4: implementation-data-type=float32
        WhlGndVelLNonDrvn_HSC4: implementation-data-type=float32
        WhlGndVelLNonDrvnV_HSC4: implementation-data-type=boolean
        PaddingGap8_3: implementation-data-type=uint8
        PaddingGap16_4: implementation-data-type=uint16
        WhlGndVelRDrvn_HSC4: implementation-data-type=float32
        WhlGndVelRDrvnV_HSC4: implementation-data-type=boolean
        PaddingGap8_5: implementation-data-type=uint8
        PaddingGap16_6: implementation-data-type=uint16
        WhlGndVelLDrvn_HSC4: implementation-data-type=float32
        WhlGndVelLDrvnV_HSC4: implementation-data-type=boolean
        PaddingGap8_7: implementation-data-type=uint8
        PaddingGap16_8: implementation-data-type=uint16
    Dt_RECORD_VCUStatus7: category=STRUCTURE
      24 x element, all with category=TYPE_REFERENCE:
        ACInCarTemHSC4: implementation-data-type=float32
        FuelLvlPcntVHSC4: implementation-data-type=boolean
        PaddingGap8_1: implementation-data-type=uint8
        PaddingGap16_2: implementation-data-type=uint16
        FuelLvlPcntHSC4: implementation-data-type=float32
        AmbtLghtLvlHSC4: implementation-data-type=uint8
        OtsdAirTemCrValV_HSC4: implementation-data-type=boolean
        PaddingGap16_3: implementation-data-type=uint16
        OtsdAirTemCrVal_HSC4: implementation-data-type=float32
        BrkLghtsStaHSC4: implementation-data-type=boolean
        DangerousWrnngLghtStaHSC4: implementation-data-type=boolean
        DipdBeamLampsStaHSC4: implementation-data-type=boolean
        FrtFogLampStaHSC4: implementation-data-type=boolean
        HornStaHSC4: implementation-data-type=boolean
        LDircnLampsStaHSC4: implementation-data-type=boolean
        MainBeamLampsStaHSC4: implementation-data-type=boolean
        RDircnLampsStaHSC4: implementation-data-type=boolean
        RevsngLghtStaHSC4: implementation-data-type=boolean
        RrFogLampStaHSC4: implementation-data-type=boolean
        WidthLampAndTaillightStateHSC4: implementation-data-type=boolean
        WiperStaHSC4: implementation-data-type=uint8
        WshrStaHSC4: implementation-data-type=boolean
        PaddingGap8_4: implementation-data-type=uint8
        PaddingGap16_5: implementation-data-type=uint16
    Dt_RECORD_VCUStatus8: category=STRUCTURE
      8 x element, all with category=TYPE_REFERENCE:
        TimeDspFmtHSC2: implementation-data-type=boolean
        SecsOfMinuteHSC2: implementation-data-type=uint8
        MinuteOfHourHSC2: implementation-data-type=uint8
        HourOfDayHSC2: implementation-data-type=uint8
        CalendarYearHSC5: implementation-data-type=uint8
        CalendarMonthHSC2: implementation-data-type=uint8
        CalendarDayHSC2: implementation-data-type=uint8
        PaddingGap8_1: implementation-data-type=uint8
    Dt_RECORD_VCUStatus9: category=STRUCTURE
      8 x element, all with category=TYPE_REFERENCE:
        VCUMainID: implementation-data-type=uint8
        VCUAddonsID: implementation-data-type=uint8
        Vehicleplatform: implementation-data-type=uint8
        VCUstage: implementation-data-type=uint8
        Projectname: implementation-data-type=uint8
        Component: implementation-data-type=uint8
        PaddingGap16_1: implementation-data-type=uint16
        VehOdoHSC2: implementation-data-type=uint32
    Dt_RECORD_VCUStatusTest1: category=STRUCTURE
      4 x element, all with category=TYPE_REFERENCE, implementation-data-type=float32:
        Test4
        Test3
        Test2
        Test1
    Dt_RECORD_VCUStatusTest2: category=STRUCTURE
      4 x element, all with category=TYPE_REFERENCE, implementation-data-type=float32:
        Test8
        Test7
        Test6
        Test5
    Dt_RECORD_VCUStatusTest3: category=STRUCTURE
      4 x element, all with category=TYPE_REFERENCE, implementation-data-type=float32:
        Test12
        Test11
        Test10
        Test9
    Dt_RECORD_VCUStatusTest4: category=STRUCTURE
      4 x element, all with category=TYPE_REFERENCE, implementation-data-type=sint16:
        Test16
        Test15
        Test14
        Test13
    Dt_RECORD_VCUVehicleInfo: category=STRUCTURE
      30 x element, all with category=TYPE_REFERENCE:
        TimeStamp: implementation-data-type=float64
        FrameID: implementation-data-type=uint8
        PaddingGap8_1: implementation-data-type=uint8
        Counter: implementation-data-type=uint16
        PaddingGap16_2: implementation-data-type=uint16
        PaddingGap16_3: implementation-data-type=uint16
        gb560: implementation-data-type=float64
        fSteeringAngle: implementation-data-type=float32
        fSpeed: implementation-data-type=float32
        fYawRate: implementation-data-type=float32
        fFrontLeftWheelSpeed: implementation-data-type=float32
        fFrontRightWheelSpeed: implementation-data-type=float32
        fRearLeftWheelSpeed: implementation-data-type=float32
        fRearRightWheelSpeed: implementation-data-type=float32
        nShifterPosition: implementation-data-type=uint8
        nLeftDirectionLamp: implementation-data-type=uint8
        nRightDirectionLamp: implementation-data-type=uint8
        nMainBeamLamp: implementation-data-type=uint8
        nDippedBeamLamp: implementation-data-type=uint8
        nWiperState: implementation-data-type=uint8
        PaddingGap16_4: implementation-data-type=uint16
        fLateralAccel: implementation-data-type=float32
        fLongituAccel: implementation-data-type=float32
        nLeftDrivenWheelPulseCounters: implementation-data-type=uint16
        nRightDrivenWheelPulseCounters: implementation-data-type=uint16
        nLeftNonDrivenWheelPulseCounters: implementation-data-type=uint16
        nRightnonDrivenWheelPulseCounters: implementation-data-type=uint16
        nDriveMode: implementation-data-type=uint8
        PaddingGap8_5: implementation-data-type=uint8
        PaddingGap16_6: implementation-data-type=uint16
    Dt_RECORD_VelNorthEast: category=STRUCTURE
      element EastVelocitysecinfo: implementation-data-type=float32
      element NorthVelocitysecinfo: implementation-data-type=float32
    Dt_RECORD_VelocityInfoRTK: category=STRUCTURE
      element DownVelocityRTK: implementation-data-type=float32
      element EastVelocityRTK: implementation-data-type=float32
      element NorthVelocityRTK: implementation-data-type=float32
    Dt_RECORD_VelocitySigma: category=STRUCTURE
      element Velnorthsigma: implementation-data-type=float32
      element Veleastsigma: implementation-data-type=float32
      element Veldownsigma: implementation-data-type=float32
    Dt_RECORD_VersionNumber: category=STRUCTURE
      4 x element, all with category=TYPE_REFERENCE, implementation-data-type=uint16:
        ARMAPPVersecinfo
        ARMBLVersecinfo
        DSPAPPVersecinfo
        DSPBLVersecinfo
    Dt_RECORD_VMS_VMSSlave: category=STRUCTURE
      10 x element, all with category=TYPE_REFERENCE:
        TimeStamp: implementation-data-type=float64
        FrameID: implementation-data-type=uint8
        PaddingGap8_1: implementation-data-type=uint8
        Counter: implementation-data-type=uint16
        Counters: implementation-data-type=uint8
        VehicleDriveModeSts: implementation-data-type=uint8
        PaddingGap16_2: implementation-data-type=uint16
        nReserved: implementation-data-type=float32
        PaddingGap16_3: implementation-data-type=uint16
        PaddingGap16_4: implementation-data-type=uint16
    Dt_RECORD_VMSSlave_VMS_100ms: category=STRUCTURE
      10 x element, all with category=TYPE_REFERENCE:
        TimeStamp: implementation-data-type=float64
        FrameID: implementation-data-type=uint8
        PaddingGap8_1: implementation-data-type=uint8
        Counter: implementation-data-type=uint16
        Counters: implementation-data-type=uint8
        PaddingGap8_2: implementation-data-type=uint8
        PaddingGap16_3: implementation-data-type=uint16
        nReserved: implementation-data-type=float32
        PaddingGap16_4: implementation-data-type=uint16
        PaddingGap16_5: implementation-data-type=uint16
package /PortInterfaces
  37 x sender receiver interface:
    PiAroundVision_SunRainSts_50ms: invalidation-policy{data-element=DeSunRainSts, handle-invalid=DONT-INVALIDATE}
      data DeSunRainSts: type=Dt_RECORD_SunRainSts
    PiCom_FSDA_FrP_60ms: invalidation-policy{data-element=DeFSDA_FrP_f1_s2, handle-invalid=DONT-INVALIDATE}
      data DeFSDA_FrP_f1_s2: type=Dt_ARRAY_32_FSDA_FrP
    PiCom_IMUinfo_10ms: invalidation-policy{data-element=DeIMUinfo, handle-invalid=DONT-INVALIDATE}
      data DeIMUinfo: type=Dt_RECORD_IMUinfo
    PiCom_RADAR_SecCH_FrP_100ms: invalidation-policy{data-element=DeRADAR_SecCH_FrP_f2_s2, handle-invalid=DONT-INVALIDATE}
      data DeRADAR_SecCH_FrP_f2_s2: type=Dt_ARRAY_32_RADAR_SecCH_FrP
    PiCom_RADAR_SecCH_FrP32_100ms: invalidation-policy{data-element=DeRADAR_SecCH_FrP32, handle-invalid=DONT-INVALIDATE}
      data DeRADAR_SecCH_FrP32: type=Dt_RECORD_RADAR_SecCH_FrP32
    PiCom_RADAR_SecCH_FrP33_100ms: invalidation-policy{data-element=DeRADAR_SecCH_FrP33, handle-invalid=DONT-INVALIDATE}
      data DeRADAR_SecCH_FrP33: type=Dt_RECORD_RADAR_SecCH_FrP33
    PiCom_RADAR_SecCH_FrP34_100ms: invalidation-policy{data-element=DeRADAR_SecCH_FrP34, handle-invalid=DONT-INVALIDATE}
      data DeRADAR_SecCH_FrP34: type=Dt_RECORD_RADAR_SecCH_FrP34
    PiCom_RDA_HSC4_P01_20ms: invalidation-policy{data-element=DeRDA_HSC4_P01, handle-invalid=DONT-INVALIDATE}
      data DeRDA_HSC4_P01: type=Dt_RECORD_RDA_HSC4_P01
    PiCom_RDA_HSC4_S00_0ms: invalidation-policy{data-element=DeRDA_HSC4_S00, handle-invalid=DONT-INVALIDATE}
      data DeRDA_HSC4_S00: type=Dt_RECORD_RDA_HSC4_S00
    PiCom_RDA_Secinfo_FrP_50ms: invalidation-policy{data-element=DeRDA_Secinfo_FrP_f2_s9, handle-invalid=DONT-INVALIDATE}
      data DeRDA_Secinfo_FrP_f2_s9: type=Dt_ARRAY_20_RDA_Secinfo_FrP
    PiCom_RDA_Secinfo_HSC4_FrP00_100ms: invalidation-policy{data-element=DeRDA_Secinfo_HSC4_FrP00, handle-invalid=DONT-INVALIDATE}
      data DeRDA_Secinfo_HSC4_FrP00: type=Dt_RECORD_RDA_Secinfo_HSC4_FrP00
    PiCom_RDA_Secinfo_HSC4_FrP02_50ms: invalidation-policy{data-element=DeRDA_Secinfo_HSC4_FrP02, handle-invalid=DONT-INVALIDATE}
      data DeRDA_Secinfo_HSC4_FrP02: type=Dt_RECORD_RDA_Secinfo_HSC4_FrP02
    PiCom_RTKinfo_100ms: invalidation-policy{data-element=DeRTKinfo, handle-invalid=DONT-INVALIDATE}
      data DeRTKinfo: type=Dt_RECORD_RTKinfo
    PiCom_UWBinfo_10ms: invalidation-policy{data-element=DeUWBinfo, handle-invalid=DONT-INVALIDATE}
      data DeUWBinfo: type=Dt_RECORD_UWBinfo
    PiIntegratedPositioning_ToVMS_10ms: invalidation-policy{data-element=DeIntegratedPositioning_ToVMS, handle-invalid=DONT-INVALIDATE}
      data DeIntegratedPositioning_ToVMS: type=Dt_RECORD_IntegratedPositioning_ToVMS
    PiMotionControl_2VMS_Status_100ms
      11 x data:
        DeCtrl_IDCCAN_IDCStatus{10..19}: type=Dt_RECORD_Ctrl_IDCCAN_IDCStatus{10..19}
        DeCtrl_IDCCAN_IDCStatus9: type=Dt_RECORD_Ctrl_IDCCAN_IDCStatus9
      invalidation-policys:
        data-element=DeCtrl_IDCCAN_IDCStatus{10..19}, handle-invalid=DONT-INVALIDATE
        data-element=DeCtrl_IDCCAN_IDCStatus9, handle-invalid=DONT-INVALIDATE
    PiMotionControl_2VMS_Status_10ms
      data DeCtrl_IDCCAN_IDCStatus{5..7}: type=Dt_RECORD_Ctrl_IDCCAN_IDCStatus{5..7}
      invalidation-policys:
        data-element=DeCtrl_IDCCAN_IDCStatus{5..7}, handle-invalid=DONT-INVALIDATE
    PiMotionControl_2VMS_Status_30ms
      4 x data:
        DeCtrl_IDCCAN_IDCStatus{1..4}: type=Dt_RECORD_Ctrl_IDCCAN_IDCStatus{1..4}
      invalidation-policys:
        data-element=DeCtrl_IDCCAN_IDCStatus{1..4}, handle-invalid=DONT-INVALIDATE
    PiPathPlanner_IDC2VMS_res1_100ms: invalidation-policy{data-element=DeIDC2VMS_res1, handle-invalid=DONT-INVALIDATE}
      data DeIDC2VMS_res1: type=Dt_RECORD_IDC2VMS_res1
    PiPathPlanner_IDC2VMS_res2_100ms: invalidation-policy{data-element=DeIDC2VMS_res2, handle-invalid=DONT-INVALIDATE}
      data DeIDC2VMS_res2: type=Dt_RECORD_IDC2VMS_res2
    PiPathPlanner_Proto_IDC2VMS_100ms: invalidation-policy{data-element=DeProto_IDC2VMS, handle-invalid=DONT-INVALIDATE}
      data DeProto_IDC2VMS: type=Dt_RECORD_Proto_IDC2VMS
    PiSecurityMonitor_FaultStatusMsg_100ms: invalidation-policy{data-element=DeFaultStatusMsg, handle-invalid=DONT-INVALIDATE}
      data DeFaultStatusMsg: type=Dt_RECORD_FaultStatusMsg
    PiVMS_iECU_255h_100ms: invalidation-policy{data-element=DeiECU_255h, handle-invalid=DONT-INVALIDATE}
      data DeiECU_255h: type=Dt_RECORD_iECU_255h
    PiVMS_iECU_256h_100ms: invalidation-policy{data-element=DeiECU_256h, handle-invalid=DONT-INVALIDATE}
      data DeiECU_256h: type=Dt_RECORD_iECU_256h
    PiVMS_iECU_25Ah_100ms: invalidation-policy{data-element=DeiECU_25Ah, handle-invalid=DONT-INVALIDATE}
      data DeiECU_25Ah: type=Dt_RECORD_iECU_25Ah
    PiVMS_IECU_25Bh_100ms: invalidation-policy{data-element=DeIECU_25Bh, handle-invalid=DONT-INVALIDATE}
      data DeIECU_25Bh: type=Dt_RECORD_IECU_25Bh
    PiVMS_VCUStatus_10ms: invalidation-policy{data-element=DeVCUStatus, handle-invalid=DONT-INVALIDATE}
      data DeVCUStatus: type=Dt_RECORD_VCUStatus
    PiVMS_VCUStatus_reserved_100ms: invalidation-policy{data-element=DeVCUStatus_reserved, handle-invalid=DONT-INVALIDATE}
      data DeVCUStatus_reserved: type=Dt_RECORD_VCUStatus_reserved
    PiVMS_VCUStatus3_20ms: invalidation-policy{data-element=DeVCUStatus3, handle-invalid=DONT-INVALIDATE}
      data DeVCUStatus3: type=Dt_RECORD_VCUStatus3
    PiVMS_VCUStatus4_50ms: invalidation-policy{data-element=DeVCUStatus4, handle-invalid=DONT-INVALIDATE}
      data DeVCUStatus4: type=Dt_RECORD_VCUStatus4
    PiVMS_VCUStatus5_100ms: invalidation-policy{data-element=DeVCUStatus5, handle-invalid=DONT-INVALIDATE}
      data DeVCUStatus5: type=Dt_RECORD_VCUStatus5
    PiVMS_VCUStatus6_50ms: invalidation-policy{data-element=DeVCUStatus6, handle-invalid=DONT-INVALIDATE}
      data DeVCUStatus6: type=Dt_RECORD_VCUStatus6
    PiVMS_VCUStatus7_200ms: invalidation-policy{data-element=DeVCUStatus7, handle-invalid=DONT-INVALIDATE}
      data DeVCUStatus7: type=Dt_RECORD_VCUStatus7
    PiVMS_VCUVehicleInfo_20ms: invalidation-policy{data-element=DeVCUVehicleInfo, handle-invalid=DONT-INVALIDATE}
      data DeVCUVehicleInfo: type=Dt_RECORD_VCUVehicleInfo
    PiVMS_VMSSlave_100ms: invalidation-policy{data-element=DeVMS_VMSSlave, handle-invalid=DONT-INVALIDATE}
      data DeVMS_VMSSlave: type=Dt_RECORD_VMS_VMSSlave
    PiVMSSlave_VMS_100ms: invalidation-policy{data-element=DeVMSSlave_VMS, handle-invalid=DONT-INVALIDATE}
      data DeVMSSlave_VMS: type=Dt_RECORD_VMSSlave_VMS_100ms
    PiXavier_UWB_EN_CMD_50ms: invalidation-policy{data-element=DeUWB_EN_CMD, handle-invalid=DONT-INVALIDATE}
      data DeUWB_EN_CMD: type=Dt_RECORD_UWB_EN_CMD
